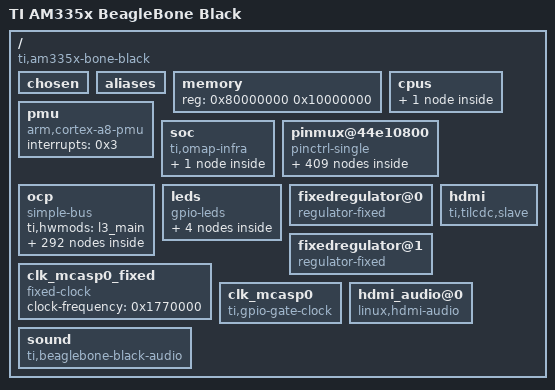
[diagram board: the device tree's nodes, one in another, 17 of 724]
/dts-v1/;

/ {
	#address-cells = <0x1>;
	#size-cells = <0x1>;
	compatible = "ti,am335x-bone-black", "ti,am335x-bone", "ti,am33xx";
	interrupt-parent = <0x1>;
	model = "TI AM335x BeagleBone Black";

	chosen {
	};

	aliases {
		i2c0 = "/ocp/i2c@44e0b000";
		i2c1 = "/ocp/i2c@4802a000";
		i2c2 = "/ocp/i2c@4819c000";
		serial0 = "/ocp/serial@44e09000";
		serial1 = "/ocp/serial@48022000";
		serial2 = "/ocp/serial@48024000";
		serial3 = "/ocp/serial@481a6000";
		serial4 = "/ocp/serial@481a8000";
		serial5 = "/ocp/serial@481aa000";
		d_can0 = "/ocp/d_can@481cc000";
		d_can1 = "/ocp/d_can@481d0000";
		usb0 = "/ocp/usb@47400000/usb@47401000";
		usb1 = "/ocp/usb@47400000/usb@47401800";
		phy0 = "/ocp/usb@47400000/usb-phy@47401300";
		phy1 = "/ocp/usb@47400000/usb-phy@47401b00";
		ethernet0 = "/ocp/ethernet@4a100000/slave@4a100200";
		ethernet1 = "/ocp/ethernet@4a100000/slave@4a100300";
	};

	memory {
		device_type = "memory";
		reg = <0x80000000 0x10000000>;
	};

	cpus {
		#address-cells = <0x1>;
		#size-cells = <0x0>;

		cpu@0 {
			compatible = "arm,cortex-a8";
			device_type = "cpu";
			reg = <0x0>;
			voltage-tolerance = <0x2>;
			clocks = <0x2>;
			clock-names = "cpu";
			clock-latency = <0x493e0>;
			cpu0-supply = <0x3>;
		};
	};

	pmu {
		compatible = "arm,cortex-a8-pmu";
		interrupts = <0x3>;
	};

	soc {
		compatible = "ti,omap-infra";

		mpu {
			compatible = "ti,omap3-mpu";
			ti,hwmods = "mpu";
		};
	};

	pinmux@44e10800 {
		compatible = "pinctrl-single";
		reg = <0x44e10800 0x238>;
		#address-cells = <0x1>;
		#size-cells = <0x0>;
		pinctrl-single,register-width = <0x20>;
		pinctrl-single,function-mask = <0x7f>;
		pinctrl-names = "default";
		pinctrl-0 = <0x4>;

		user_leds_default {
			pinctrl-single,pins = <0x54 0x7 0x58 0x17 0x5c 0x7 0x60 0x17>;
			linux,phandle = <0x1b0>;
			phandle = <0x1b0>;
		};

		user_leds_sleep {
			pinctrl-single,pins = <0x54 0x27 0x58 0x27 0x5c 0x27 0x60 0x27>;
			linux,phandle = <0x1b1>;
			phandle = <0x1b1>;
		};

		user_leds_s1 {
			pinctrl-single,pins = <0x98 0x7 0x9c 0x7>;
		};

		pinmux_gpio1_17_pins {
			pinctrl-single,pins = <0x44 0x27>;
		};

		pinmux_gpio1_18_led_pins {
			pinctrl-single,pins = <0x48 0x7>;
		};

		pinmux_gpio1_28_led_pins {
			pinctrl-single,pins = <0x78 0x2f>;
		};

		pinmux_gpio1_29_pins {
			pinctrl-single,pins = <0x7c 0x3f>;
		};

		pinmux_gpio3_19_led_pins {
			pinctrl-single,pins = <0x1a4 0x7>;
		};

		bbcape_backlight_pins {
			pinctrl-single,pins = <0x48 0xf>;
		};

		pinmux_i2c0_pins {
			pinctrl-single,pins = <0x188 0x30 0x18c 0x30>;
			linux,phandle = <0x26>;
			phandle = <0x26>;
		};

		pinmux_i2c1_pins {
			pinctrl-single,pins = <0x158 0x72 0x15c 0x72>;
		};

		pinmux_i2c2_pins {
			pinctrl-single,pins = <0x178 0x73 0x17c 0x73>;
			linux,phandle = <0x27>;
			phandle = <0x27>;
		};

		pinmux_spi0_pins {
			pinctrl-single,pins = <0x150 0x30 0x154 0x30 0x158 0x10 0x15c 0x10>;
		};

		pinmux_spi1_pins {
			pinctrl-single,pins = <0x190 0x33 0x194 0x33 0x198 0x13 0x19c 0x13>;
		};

		pinmux_spi1a_pins {
			pinctrl-single,pins = <0x164 0x34 0x194 0x33 0x198 0x13 0x178 0x14>;
		};

		pinmux_uart0_pins {
			pinctrl-single,pins = <0x170 0x30 0x174 0x0>;
			linux,phandle = <0x25>;
			phandle = <0x25>;
		};

		pinmux_bbcape_crypto_pins {
			pinctrl-single,pins = <0x44 0x17 0x34 0x2f>;
		};

		bbcape_lcd_pins {
			pinctrl-single,pins = <0xa0 0x8 0xa4 0x8 0xa8 0x8 0xac 0x8 0xb0 0x8 0xb4 0x8 0xb8 0x8 0xbc 0x8 0xc0 0x8 0xc4 0x8 0xc8 0x8 0xcc 0x8 0xd0 0x8 0xd4 0x8 0xd8 0x8 0xdc 0x8 0xe0 0x8 0xe4 0x8 0xe8 0x8 0xec 0x8>;
		};

		bbcape_lcd_24bit_pins {
			pinctrl-single,pins = <0xa0 0x0 0xa4 0x0 0xa8 0x0 0xac 0x0 0xb0 0x0 0xb4 0x0 0xb8 0x0 0xbc 0x0 0xc0 0x0 0xc4 0x0 0xc8 0x0 0xcc 0x0 0xd0 0x0 0xd4 0x0 0xd8 0x0 0xdc 0x0 0x3c 0x11 0x38 0x11 0x34 0x11 0x30 0x11 0x2c 0x11 0x28 0x11 0x24 0x11 0x20 0x11 0xe0 0x0 0xe4 0x0 0xe8 0x0 0xec 0x0>;
		};

		bbcape_lcd7_avdd_en {
			pinctrl-single,pins = <0x150 0x17>;
		};

		bbcape_lcd4_disen_pins {
			pinctrl-single,pins = <0x1a4 0x17>;
		};

		pinmux_clkout2_pin {
			pinctrl-single,pins = <0x1b4 0x3>;
			linux,phandle = <0x4>;
			phandle = <0x4>;
		};

		cpsw_default {
			pinctrl-single,pins = <0x110 0x30 0x114 0x0 0x118 0x30 0x11c 0x0 0x120 0x0 0x124 0x0 0x128 0x0 0x12c 0x30 0x130 0x30 0x134 0x30 0x138 0x30 0x13c 0x30 0x140 0x30>;
			linux,phandle = <0x35>;
			phandle = <0x35>;
		};

		cpsw_sleep {
			pinctrl-single,pins = <0x110 0x27 0x114 0x27 0x118 0x27 0x11c 0x27 0x120 0x27 0x124 0x27 0x128 0x27 0x12c 0x27 0x130 0x27 0x134 0x27 0x138 0x27 0x13c 0x27 0x140 0x27>;
			linux,phandle = <0x36>;
			phandle = <0x36>;
		};

		davinci_mdio_default {
			pinctrl-single,pins = <0x148 0x70 0x14c 0x10>;
			linux,phandle = <0x37>;
			phandle = <0x37>;
		};

		davinci_mdio_sleep {
			pinctrl-single,pins = <0x148 0x27 0x14c 0x27>;
			linux,phandle = <0x38>;
			phandle = <0x38>;
		};

		pinmux_mmc1_pins {
			pinctrl-single,pins = <0xf0 0x30 0xf4 0x30 0xf8 0x30 0xfc 0x30 0x100 0x30 0x104 0x30 0x1a0 0x37 0x160 0x2f>;
			linux,phandle = <0x29>;
			phandle = <0x29>;
		};

		pinmux_mmc1_pins_sleep {
			pinctrl-single,pins = <0xf0 0x27 0xf4 0x27 0xf8 0x27 0xfc 0x27 0x100 0x27 0x104 0x27 0x1a0 0x27>;
			linux,phandle = <0x2a>;
			phandle = <0x2a>;
		};

		pinmux_emmc_pins {
			pinctrl-single,pins = <0x80 0x32 0x84 0x32 0x0 0x31 0x4 0x31 0x8 0x31 0xc 0x31 0x10 0x31 0x14 0x31 0x18 0x31 0x1c 0x31>;
			linux,phandle = <0x2d>;
			phandle = <0x2d>;
		};

		nxp_hdmi_bonelt_pins {
			pinctrl-single,pins = <0x1b0 0x3 0xa0 0x8 0xa4 0x8 0xa8 0x8 0xac 0x8 0xb0 0x8 0xb4 0x8 0xb8 0x8 0xbc 0x8 0xc0 0x8 0xc4 0x8 0xc8 0x8 0xcc 0x8 0xd0 0x8 0xd4 0x8 0xd8 0x8 0xdc 0x8 0xe0 0x0 0xe4 0x0 0xe8 0x0 0xec 0x0>;
		};

		nxp_hdmi_bonelt_off_pins {
			pinctrl-single,pins = <0x1b0 0x3>;
			linux,phandle = <0x1b3>;
			phandle = <0x1b3>;
		};

		pinmux_keymap0_pins {
			pinctrl-single,pins = <0x40 0x2f 0x44 0x2f 0x4c 0x2f 0x198 0x2f 0x154 0x2f>;
		};

		pinmux_keymap1_pins {
			pinctrl-single,pins = <0x40 0x2f 0x44 0x2f 0x4c 0x2f 0x198 0x2f 0x184 0x2f>;
		};

		pinmux_keymap2_pins {
			pinctrl-single,pins = <0x40 0x2f 0x44 0x2f 0x4c 0x2f 0x198 0x2f 0x1a4 0x2f>;
		};

		pinmux_keymap3_pins {
			pinctrl-single,pins = <0x40 0x2f 0x4c 0x2f 0x78 0x2f 0x164 0x2f 0x1a4 0x2f>;
		};

		pinmux_keymap4_pins {
			pinctrl-single,pins = <0x44 0x2f 0x4c 0x2f 0x70 0x2f 0x184 0x2f>;
		};

		mcasp0_pins {
			pinctrl-single,pins = <0x1ac 0x30 0x19c 0x2 0x194 0x10 0x190 0x0 0x6c 0x7>;
		};

		mcasp0_pins_sleep {
			pinctrl-single,pins = <0x1ac 0x27 0x19c 0x27 0x194 0x27 0x190 0x27 0x6c 0x27>;
		};

		mcasp0_clken {
			pinctrl-single,pins = <0x6c 0x7>;
			linux,phandle = <0x3e>;
			phandle = <0x3e>;
		};

		mcasp0_pins_audio_reva {
			pinctrl-single,pins = <0x190 0x20 0x194 0x20 0x19c 0x22 0x1ac 0x22>;
		};

		mcasp0_pins_audio_revb {
			pinctrl-single,pins = <0x1ac 0x0 0x190 0x20 0x194 0x20 0x198 0x20 0x19c 0x22>;
		};

		mcasp0_pins_audio2 {
			pinctrl-single,pins = <0x190 0x20 0x194 0x20 0x198 0x20 0x19c 0x22>;
		};

		pinmux_P8_07_default_pin {
			pinctrl-single,pins = <0x90 0x37>;
			linux,phandle = <0x3f>;
			phandle = <0x3f>;
		};

		pinmux_P8_07_gpio_pin {
			pinctrl-single,pins = <0x90 0x2f>;
			linux,phandle = <0x40>;
			phandle = <0x40>;
		};

		pinmux_P8_07_gpio_pu_pin {
			pinctrl-single,pins = <0x90 0x37>;
			linux,phandle = <0x41>;
			phandle = <0x41>;
		};

		pinmux_P8_07_gpio_pd_pin {
			pinctrl-single,pins = <0x90 0x27>;
			linux,phandle = <0x42>;
			phandle = <0x42>;
		};

		pinmux_P8_07_timer_pin {
			pinctrl-single,pins = <0x90 0x32>;
			linux,phandle = <0x43>;
			phandle = <0x43>;
		};

		pinmux_P8_08_default_pin {
			pinctrl-single,pins = <0x94 0x37>;
			linux,phandle = <0x44>;
			phandle = <0x44>;
		};

		pinmux_P8_08_gpio_pin {
			pinctrl-single,pins = <0x94 0x2f>;
			linux,phandle = <0x45>;
			phandle = <0x45>;
		};

		pinmux_P8_08_gpio_pu_pin {
			pinctrl-single,pins = <0x94 0x37>;
			linux,phandle = <0x46>;
			phandle = <0x46>;
		};

		pinmux_P8_08_gpio_pd_pin {
			pinctrl-single,pins = <0x94 0x27>;
			linux,phandle = <0x47>;
			phandle = <0x47>;
		};

		pinmux_P8_08_timer_pin {
			pinctrl-single,pins = <0x94 0x32>;
			linux,phandle = <0x48>;
			phandle = <0x48>;
		};

		pinmux_P8_09_default_pin {
			pinctrl-single,pins = <0x9c 0x37>;
			linux,phandle = <0x49>;
			phandle = <0x49>;
		};

		pinmux_P8_09_gpio_pin {
			pinctrl-single,pins = <0x9c 0x2f>;
			linux,phandle = <0x4a>;
			phandle = <0x4a>;
		};

		pinmux_P8_09_gpio_pu_pin {
			pinctrl-single,pins = <0x9c 0x37>;
			linux,phandle = <0x4b>;
			phandle = <0x4b>;
		};

		pinmux_P8_09_gpio_pd_pin {
			pinctrl-single,pins = <0x9c 0x27>;
			linux,phandle = <0x4c>;
			phandle = <0x4c>;
		};

		pinmux_P8_09_timer_pin {
			pinctrl-single,pins = <0x9c 0x32>;
			linux,phandle = <0x4d>;
			phandle = <0x4d>;
		};

		pinmux_P8_10_default_pin {
			pinctrl-single,pins = <0x98 0x37>;
			linux,phandle = <0x4e>;
			phandle = <0x4e>;
		};

		pinmux_P8_10_gpio_pin {
			pinctrl-single,pins = <0x98 0x2f>;
			linux,phandle = <0x4f>;
			phandle = <0x4f>;
		};

		pinmux_P8_10_gpio_pu_pin {
			pinctrl-single,pins = <0x98 0x37>;
			linux,phandle = <0x50>;
			phandle = <0x50>;
		};

		pinmux_P8_10_gpio_pd_pin {
			pinctrl-single,pins = <0x98 0x27>;
			linux,phandle = <0x51>;
			phandle = <0x51>;
		};

		pinmux_P8_10_timer_pin {
			pinctrl-single,pins = <0x98 0x32>;
			linux,phandle = <0x52>;
			phandle = <0x52>;
		};

		pinmux_P8_11_default_pin {
			pinctrl-single,pins = <0x34 0x27>;
			linux,phandle = <0x53>;
			phandle = <0x53>;
		};

		pinmux_P8_11_gpio_pin {
			pinctrl-single,pins = <0x34 0x2f>;
			linux,phandle = <0x54>;
			phandle = <0x54>;
		};

		pinmux_P8_11_gpio_pu_pin {
			pinctrl-single,pins = <0x34 0x37>;
			linux,phandle = <0x55>;
			phandle = <0x55>;
		};

		pinmux_P8_11_gpio_pd_pin {
			pinctrl-single,pins = <0x34 0x27>;
			linux,phandle = <0x56>;
			phandle = <0x56>;
		};

		pinmux_P8_11_pruout_pin {
			pinctrl-single,pins = <0x34 0x26>;
			linux,phandle = <0x57>;
			phandle = <0x57>;
		};

		pinmux_P8_11_qep_pin {
			pinctrl-single,pins = <0x34 0x24>;
			linux,phandle = <0x58>;
			phandle = <0x58>;
		};

		pinmux_P8_12_default_pin {
			pinctrl-single,pins = <0x30 0x27>;
			linux,phandle = <0x59>;
			phandle = <0x59>;
		};

		pinmux_P8_12_gpio_pin {
			pinctrl-single,pins = <0x30 0x2f>;
			linux,phandle = <0x5a>;
			phandle = <0x5a>;
		};

		pinmux_P8_12_gpio_pu_pin {
			pinctrl-single,pins = <0x30 0x37>;
			linux,phandle = <0x5b>;
			phandle = <0x5b>;
		};

		pinmux_P8_12_gpio_pd_pin {
			pinctrl-single,pins = <0x30 0x27>;
			linux,phandle = <0x5c>;
			phandle = <0x5c>;
		};

		pinmux_P8_12_pruout_pin {
			pinctrl-single,pins = <0x30 0x26>;
			linux,phandle = <0x5d>;
			phandle = <0x5d>;
		};

		pinmux_P8_12_qep_pin {
			pinctrl-single,pins = <0x30 0x24>;
			linux,phandle = <0x5e>;
			phandle = <0x5e>;
		};

		pinmux_P8_13_default_pin {
			pinctrl-single,pins = <0x24 0x27>;
			linux,phandle = <0x5f>;
			phandle = <0x5f>;
		};

		pinmux_P8_13_gpio_pin {
			pinctrl-single,pins = <0x24 0x2f>;
			linux,phandle = <0x60>;
			phandle = <0x60>;
		};

		pinmux_P8_13_gpio_pu_pin {
			pinctrl-single,pins = <0x24 0x37>;
			linux,phandle = <0x61>;
			phandle = <0x61>;
		};

		pinmux_P8_13_gpio_pd_pin {
			pinctrl-single,pins = <0x24 0x27>;
			linux,phandle = <0x62>;
			phandle = <0x62>;
		};

		pinmux_P8_13_pwm_pin {
			pinctrl-single,pins = <0x24 0x24>;
			linux,phandle = <0x63>;
			phandle = <0x63>;
		};

		pinmux_P8_14_default_pin {
			pinctrl-single,pins = <0x28 0x27>;
			linux,phandle = <0x64>;
			phandle = <0x64>;
		};

		pinmux_P8_14_gpio_pin {
			pinctrl-single,pins = <0x28 0x2f>;
			linux,phandle = <0x65>;
			phandle = <0x65>;
		};

		pinmux_P8_14_gpio_pu_pin {
			pinctrl-single,pins = <0x28 0x37>;
			linux,phandle = <0x66>;
			phandle = <0x66>;
		};

		pinmux_P8_14_gpio_pd_pin {
			pinctrl-single,pins = <0x28 0x27>;
			linux,phandle = <0x67>;
			phandle = <0x67>;
		};

		pinmux_P8_14_pwm_pin {
			pinctrl-single,pins = <0x28 0x24>;
			linux,phandle = <0x68>;
			phandle = <0x68>;
		};

		pinmux_P8_15_default_pin {
			pinctrl-single,pins = <0x3c 0x27>;
			linux,phandle = <0x69>;
			phandle = <0x69>;
		};

		pinmux_P8_15_gpio_pin {
			pinctrl-single,pins = <0x3c 0x2f>;
			linux,phandle = <0x6a>;
			phandle = <0x6a>;
		};

		pinmux_P8_15_gpio_pu_pin {
			pinctrl-single,pins = <0x3c 0x37>;
			linux,phandle = <0x6b>;
			phandle = <0x6b>;
		};

		pinmux_P8_15_gpio_pd_pin {
			pinctrl-single,pins = <0x3c 0x27>;
			linux,phandle = <0x6c>;
			phandle = <0x6c>;
		};

		pinmux_P8_15_pruin_pin {
			pinctrl-single,pins = <0x3c 0x26>;
			linux,phandle = <0x6d>;
			phandle = <0x6d>;
		};

		pinmux_P8_15_qep_pin {
			pinctrl-single,pins = <0x3c 0x24>;
			linux,phandle = <0x6e>;
			phandle = <0x6e>;
		};

		pinmux_P8_16_default_pin {
			pinctrl-single,pins = <0x38 0x27>;
			linux,phandle = <0x6f>;
			phandle = <0x6f>;
		};

		pinmux_P8_16_gpio_pin {
			pinctrl-single,pins = <0x38 0x2f>;
			linux,phandle = <0x70>;
			phandle = <0x70>;
		};

		pinmux_P8_16_gpio_pu_pin {
			pinctrl-single,pins = <0x38 0x37>;
			linux,phandle = <0x71>;
			phandle = <0x71>;
		};

		pinmux_P8_16_gpio_pd_pin {
			pinctrl-single,pins = <0x38 0x27>;
			linux,phandle = <0x72>;
			phandle = <0x72>;
		};

		pinmux_P8_16_pruin_pin {
			pinctrl-single,pins = <0x38 0x26>;
			linux,phandle = <0x73>;
			phandle = <0x73>;
		};

		pinmux_P8_16_qep_pin {
			pinctrl-single,pins = <0x38 0x24>;
			linux,phandle = <0x74>;
			phandle = <0x74>;
		};

		pinmux_P8_17_default_pin {
			pinctrl-single,pins = <0x2c 0x27>;
			linux,phandle = <0x75>;
			phandle = <0x75>;
		};

		pinmux_P8_17_gpio_pin {
			pinctrl-single,pins = <0x2c 0x2f>;
			linux,phandle = <0x76>;
			phandle = <0x76>;
		};

		pinmux_P8_17_gpio_pu_pin {
			pinctrl-single,pins = <0x2c 0x37>;
			linux,phandle = <0x77>;
			phandle = <0x77>;
		};

		pinmux_P8_17_gpio_pd_pin {
			pinctrl-single,pins = <0x2c 0x27>;
			linux,phandle = <0x78>;
			phandle = <0x78>;
		};

		pinmux_P8_17_pwm_pin {
			pinctrl-single,pins = <0x2c 0x24>;
			linux,phandle = <0x79>;
			phandle = <0x79>;
		};

		pinmux_P8_18_default_pin {
			pinctrl-single,pins = <0x8c 0x27>;
			linux,phandle = <0x7a>;
			phandle = <0x7a>;
		};

		pinmux_P8_18_gpio_pin {
			pinctrl-single,pins = <0x8c 0x2f>;
			linux,phandle = <0x7b>;
			phandle = <0x7b>;
		};

		pinmux_P8_18_gpio_pu_pin {
			pinctrl-single,pins = <0x8c 0x37>;
			linux,phandle = <0x7c>;
			phandle = <0x7c>;
		};

		pinmux_P8_18_gpio_pd_pin {
			pinctrl-single,pins = <0x8c 0x27>;
			linux,phandle = <0x7d>;
			phandle = <0x7d>;
		};

		pinmux_P8_19_default_pin {
			pinctrl-single,pins = <0x20 0x27>;
			linux,phandle = <0x7e>;
			phandle = <0x7e>;
		};

		pinmux_P8_19_gpio_pin {
			pinctrl-single,pins = <0x20 0x2f>;
			linux,phandle = <0x7f>;
			phandle = <0x7f>;
		};

		pinmux_P8_19_gpio_pu_pin {
			pinctrl-single,pins = <0x20 0x37>;
			linux,phandle = <0x80>;
			phandle = <0x80>;
		};

		pinmux_P8_19_gpio_pd_pin {
			pinctrl-single,pins = <0x20 0x27>;
			linux,phandle = <0x81>;
			phandle = <0x81>;
		};

		pinmux_P8_19_pwm_pin {
			pinctrl-single,pins = <0x20 0x24>;
			linux,phandle = <0x82>;
			phandle = <0x82>;
		};

		pinmux_P8_26_default_pin {
			pinctrl-single,pins = <0x7c 0x37>;
			linux,phandle = <0x83>;
			phandle = <0x83>;
		};

		pinmux_P8_26_gpio_pin {
			pinctrl-single,pins = <0x7c 0x2f>;
			linux,phandle = <0x84>;
			phandle = <0x84>;
		};

		pinmux_P8_26_gpio_pu_pin {
			pinctrl-single,pins = <0x7c 0x37>;
			linux,phandle = <0x85>;
			phandle = <0x85>;
		};

		pinmux_P8_26_gpio_pd_pin {
			pinctrl-single,pins = <0x7c 0x27>;
			linux,phandle = <0x86>;
			phandle = <0x86>;
		};

		pinmux_P8_27_default_pin {
			pinctrl-single,pins = <0xe0 0x27>;
			linux,phandle = <0x87>;
			phandle = <0x87>;
		};

		pinmux_P8_27_gpio_pin {
			pinctrl-single,pins = <0xe0 0x2f>;
			linux,phandle = <0x88>;
			phandle = <0x88>;
		};

		pinmux_P8_27_gpio_pu_pin {
			pinctrl-single,pins = <0xe0 0x37>;
			linux,phandle = <0x89>;
			phandle = <0x89>;
		};

		pinmux_P8_27_gpio_pd_pin {
			pinctrl-single,pins = <0xe0 0x27>;
			linux,phandle = <0x8a>;
			phandle = <0x8a>;
		};

		pinmux_P8_27_pruout_pin {
			pinctrl-single,pins = <0xe0 0x5>;
			linux,phandle = <0x8b>;
			phandle = <0x8b>;
		};

		pinmux_P8_27_pruin_pin {
			pinctrl-single,pins = <0xe0 0x26>;
			linux,phandle = <0x8c>;
			phandle = <0x8c>;
		};

		pinmux_P8_27_hdmi_pin {
			pinctrl-single,pins = <0xe0 0x0>;
			linux,phandle = <0x8d>;
			phandle = <0x8d>;
		};

		pinmux_P8_28_default_pin {
			pinctrl-single,pins = <0xe8 0x27>;
			linux,phandle = <0x8e>;
			phandle = <0x8e>;
		};

		pinmux_P8_28_gpio_pin {
			pinctrl-single,pins = <0xe8 0x2f>;
			linux,phandle = <0x8f>;
			phandle = <0x8f>;
		};

		pinmux_P8_28_gpio_pu_pin {
			pinctrl-single,pins = <0xe8 0x37>;
			linux,phandle = <0x90>;
			phandle = <0x90>;
		};

		pinmux_P8_28_gpio_pd_pin {
			pinctrl-single,pins = <0xe8 0x27>;
			linux,phandle = <0x91>;
			phandle = <0x91>;
		};

		pinmux_P8_28_pruout_pin {
			pinctrl-single,pins = <0xe8 0x5>;
			linux,phandle = <0x92>;
			phandle = <0x92>;
		};

		pinmux_P8_28_pruin_pin {
			pinctrl-single,pins = <0xe8 0x26>;
			linux,phandle = <0x93>;
			phandle = <0x93>;
		};

		pinmux_P8_28_hdmi_pin {
			pinctrl-single,pins = <0xe8 0x0>;
			linux,phandle = <0x94>;
			phandle = <0x94>;
		};

		pinmux_P8_29_default_pin {
			pinctrl-single,pins = <0xe4 0x27>;
			linux,phandle = <0x95>;
			phandle = <0x95>;
		};

		pinmux_P8_29_gpio_pin {
			pinctrl-single,pins = <0xe4 0x2f>;
			linux,phandle = <0x96>;
			phandle = <0x96>;
		};

		pinmux_P8_29_gpio_pu_pin {
			pinctrl-single,pins = <0xe4 0x37>;
			linux,phandle = <0x97>;
			phandle = <0x97>;
		};

		pinmux_P8_29_gpio_pd_pin {
			pinctrl-single,pins = <0xe4 0x27>;
			linux,phandle = <0x98>;
			phandle = <0x98>;
		};

		pinmux_P8_29_pruout_pin {
			pinctrl-single,pins = <0xe4 0x5>;
			linux,phandle = <0x99>;
			phandle = <0x99>;
		};

		pinmux_P8_29_pruin_pin {
			pinctrl-single,pins = <0xe4 0x26>;
			linux,phandle = <0x9a>;
			phandle = <0x9a>;
		};

		pinmux_P8_29_hdmi_pin {
			pinctrl-single,pins = <0xe4 0x0>;
			linux,phandle = <0x9b>;
			phandle = <0x9b>;
		};

		pinmux_P8_30_default_pin {
			pinctrl-single,pins = <0xec 0x27>;
			linux,phandle = <0x9c>;
			phandle = <0x9c>;
		};

		pinmux_P8_30_gpio_pin {
			pinctrl-single,pins = <0xec 0x2f>;
			linux,phandle = <0x9d>;
			phandle = <0x9d>;
		};

		pinmux_P8_30_gpio_pu_pin {
			pinctrl-single,pins = <0xec 0x37>;
			linux,phandle = <0x9e>;
			phandle = <0x9e>;
		};

		pinmux_P8_30_gpio_pd_pin {
			pinctrl-single,pins = <0xec 0x27>;
			linux,phandle = <0x9f>;
			phandle = <0x9f>;
		};

		pinmux_P8_30_pruout_pin {
			pinctrl-single,pins = <0xec 0x5>;
			linux,phandle = <0xa0>;
			phandle = <0xa0>;
		};

		pinmux_P8_30_pruin_pin {
			pinctrl-single,pins = <0xec 0x26>;
			linux,phandle = <0xa1>;
			phandle = <0xa1>;
		};

		pinmux_P8_30_hdmi_pin {
			pinctrl-single,pins = <0xec 0x0>;
			linux,phandle = <0xa2>;
			phandle = <0xa2>;
		};

		pinmux_P8_31_default_pin {
			pinctrl-single,pins = <0xd8 0x27>;
			linux,phandle = <0xa3>;
			phandle = <0xa3>;
		};

		pinmux_P8_31_gpio_pin {
			pinctrl-single,pins = <0xd8 0x2f>;
			linux,phandle = <0xa4>;
			phandle = <0xa4>;
		};

		pinmux_P8_31_gpio_pu_pin {
			pinctrl-single,pins = <0xd8 0x37>;
			linux,phandle = <0xa5>;
			phandle = <0xa5>;
		};

		pinmux_P8_31_gpio_pd_pin {
			pinctrl-single,pins = <0xd8 0x27>;
			linux,phandle = <0xa6>;
			phandle = <0xa6>;
		};

		pinmux_P8_31_uart_pin {
			pinctrl-single,pins = <0xd8 0x24>;
			linux,phandle = <0xa7>;
			phandle = <0xa7>;
		};

		pinmux_P8_31_hdmi_pin {
			pinctrl-single,pins = <0xd8 0x8>;
			linux,phandle = <0xa8>;
			phandle = <0xa8>;
		};

		pinmux_P8_32_default_pin {
			pinctrl-single,pins = <0xdc 0x27>;
			linux,phandle = <0xa9>;
			phandle = <0xa9>;
		};

		pinmux_P8_32_gpio_pin {
			pinctrl-single,pins = <0xdc 0x2f>;
			linux,phandle = <0xaa>;
			phandle = <0xaa>;
		};

		pinmux_P8_32_gpio_pu_pin {
			pinctrl-single,pins = <0xdc 0x37>;
			linux,phandle = <0xab>;
			phandle = <0xab>;
		};

		pinmux_P8_32_gpio_pd_pin {
			pinctrl-single,pins = <0xdc 0x27>;
			linux,phandle = <0xac>;
			phandle = <0xac>;
		};

		pinmux_P8_32_uart_pin {
			pinctrl-single,pins = <0xdc 0x26>;
		};

		pinmux_P8_32_hdmi_pin {
			pinctrl-single,pins = <0xdc 0x8>;
			linux,phandle = <0xad>;
			phandle = <0xad>;
		};

		pinmux_P8_33_default_pin {
			pinctrl-single,pins = <0xd4 0x27>;
			linux,phandle = <0xae>;
			phandle = <0xae>;
		};

		pinmux_P8_33_gpio_pin {
			pinctrl-single,pins = <0xd4 0x2f>;
			linux,phandle = <0xaf>;
			phandle = <0xaf>;
		};

		pinmux_P8_33_gpio_pu_pin {
			pinctrl-single,pins = <0xd4 0x37>;
			linux,phandle = <0xb0>;
			phandle = <0xb0>;
		};

		pinmux_P8_33_gpio_pd_pin {
			pinctrl-single,pins = <0xd4 0x27>;
			linux,phandle = <0xb1>;
			phandle = <0xb1>;
		};

		pinmux_P8_33_hdmi_pin {
			pinctrl-single,pins = <0xd4 0x8>;
			linux,phandle = <0xb2>;
			phandle = <0xb2>;
		};

		pinmux_P8_34_default_pin {
			pinctrl-single,pins = <0xcc 0x27>;
			linux,phandle = <0xb3>;
			phandle = <0xb3>;
		};

		pinmux_P8_34_gpio_pin {
			pinctrl-single,pins = <0xcc 0x2f>;
			linux,phandle = <0xb4>;
			phandle = <0xb4>;
		};

		pinmux_P8_34_gpio_pu_pin {
			pinctrl-single,pins = <0xcc 0x37>;
			linux,phandle = <0xb5>;
			phandle = <0xb5>;
		};

		pinmux_P8_34_gpio_pd_pin {
			pinctrl-single,pins = <0xcc 0x27>;
			linux,phandle = <0xb6>;
			phandle = <0xb6>;
		};

		pinmux_P8_34_pwm_pin {
			pinctrl-single,pins = <0xcc 0x22>;
			linux,phandle = <0xb7>;
			phandle = <0xb7>;
		};

		pinmux_P8_34_hdmi_pin {
			pinctrl-single,pins = <0xcc 0x8>;
			linux,phandle = <0xb8>;
			phandle = <0xb8>;
		};

		pinmux_P8_35_default_pin {
			pinctrl-single,pins = <0xd0 0x27>;
			linux,phandle = <0xb9>;
			phandle = <0xb9>;
		};

		pinmux_P8_35_gpio_pin {
			pinctrl-single,pins = <0xd0 0x2f>;
			linux,phandle = <0xba>;
			phandle = <0xba>;
		};

		pinmux_P8_35_gpio_pu_pin {
			pinctrl-single,pins = <0xd0 0x37>;
			linux,phandle = <0xbb>;
			phandle = <0xbb>;
		};

		pinmux_P8_35_gpio_pd_pin {
			pinctrl-single,pins = <0xd0 0x27>;
			linux,phandle = <0xbc>;
			phandle = <0xbc>;
		};

		pinmux_P8_35_hdmi_pin {
			pinctrl-single,pins = <0xd0 0x8>;
			linux,phandle = <0xbd>;
			phandle = <0xbd>;
		};

		pinmux_P8_36_default_pin {
			pinctrl-single,pins = <0xc8 0x27>;
			linux,phandle = <0xbe>;
			phandle = <0xbe>;
		};

		pinmux_P8_36_gpio_pin {
			pinctrl-single,pins = <0xc8 0x2f>;
			linux,phandle = <0xbf>;
			phandle = <0xbf>;
		};

		pinmux_P8_36_gpio_pu_pin {
			pinctrl-single,pins = <0xc8 0x37>;
			linux,phandle = <0xc0>;
			phandle = <0xc0>;
		};

		pinmux_P8_36_gpio_pd_pin {
			pinctrl-single,pins = <0xc8 0x27>;
			linux,phandle = <0xc1>;
			phandle = <0xc1>;
		};

		pinmux_P8_36_pwm_pin {
			pinctrl-single,pins = <0xc8 0x22>;
			linux,phandle = <0xc2>;
			phandle = <0xc2>;
		};

		pinmux_P8_36_hdmi_pin {
			pinctrl-single,pins = <0xc8 0x8>;
			linux,phandle = <0xc3>;
			phandle = <0xc3>;
		};

		pinmux_P8_37_default_pin {
			pinctrl-single,pins = <0xc0 0x27>;
			linux,phandle = <0xc4>;
			phandle = <0xc4>;
		};

		pinmux_P8_37_gpio_pin {
			pinctrl-single,pins = <0xc0 0x2f>;
			linux,phandle = <0xc5>;
			phandle = <0xc5>;
		};

		pinmux_P8_37_gpio_pu_pin {
			pinctrl-single,pins = <0xc0 0x37>;
			linux,phandle = <0xc6>;
			phandle = <0xc6>;
		};

		pinmux_P8_37_gpio_pd_pin {
			pinctrl-single,pins = <0xc0 0x27>;
			linux,phandle = <0xc7>;
			phandle = <0xc7>;
		};

		pinmux_P8_37_uart_pin {
			pinctrl-single,pins = <0xc0 0x4>;
			linux,phandle = <0xc8>;
			phandle = <0xc8>;
		};

		pinmux_P8_37_pwm_pin {
			pinctrl-single,pins = <0xc0 0x2>;
			linux,phandle = <0xc9>;
			phandle = <0xc9>;
		};

		pinmux_P8_37_hdmi_pin {
			pinctrl-single,pins = <0xc0 0x8>;
			linux,phandle = <0xca>;
			phandle = <0xca>;
		};

		pinmux_P8_38_default_pin {
			pinctrl-single,pins = <0xc4 0x27>;
			linux,phandle = <0xcb>;
			phandle = <0xcb>;
		};

		pinmux_P8_38_gpio_pin {
			pinctrl-single,pins = <0xc4 0x2f>;
			linux,phandle = <0xcc>;
			phandle = <0xcc>;
		};

		pinmux_P8_38_gpio_pu_pin {
			pinctrl-single,pins = <0xc4 0x37>;
			linux,phandle = <0xcd>;
			phandle = <0xcd>;
		};

		pinmux_P8_38_gpio_pd_pin {
			pinctrl-single,pins = <0xc4 0x27>;
			linux,phandle = <0xce>;
			phandle = <0xce>;
		};

		pinmux_P8_38_uart_pin {
			pinctrl-single,pins = <0xc4 0x24>;
			linux,phandle = <0xcf>;
			phandle = <0xcf>;
		};

		pinmux_P8_38_pwm_pin {
			pinctrl-single,pins = <0xc4 0x22>;
			linux,phandle = <0xd0>;
			phandle = <0xd0>;
		};

		pinmux_P8_38_hdmi_pin {
			pinctrl-single,pins = <0xc4 0x8>;
			linux,phandle = <0xd1>;
			phandle = <0xd1>;
		};

		pinmux_P8_39_default_pin {
			pinctrl-single,pins = <0xb8 0x27>;
			linux,phandle = <0xd2>;
			phandle = <0xd2>;
		};

		pinmux_P8_39_gpio_pin {
			pinctrl-single,pins = <0xb8 0x2f>;
			linux,phandle = <0xd3>;
			phandle = <0xd3>;
		};

		pinmux_P8_39_gpio_pu_pin {
			pinctrl-single,pins = <0xb8 0x37>;
			linux,phandle = <0xd4>;
			phandle = <0xd4>;
		};

		pinmux_P8_39_gpio_pd_pin {
			pinctrl-single,pins = <0xb8 0x27>;
			linux,phandle = <0xd5>;
			phandle = <0xd5>;
		};

		pinmux_P8_39_pruout_pin {
			pinctrl-single,pins = <0xb8 0x5>;
			linux,phandle = <0xd6>;
			phandle = <0xd6>;
		};

		pinmux_P8_39_pruin_pin {
			pinctrl-single,pins = <0xb8 0x26>;
			linux,phandle = <0xd7>;
			phandle = <0xd7>;
		};

		pinmux_P8_39_hdmi_pin {
			pinctrl-single,pins = <0xb8 0x8>;
			linux,phandle = <0xd8>;
			phandle = <0xd8>;
		};

		pinmux_P8_40_default_pin {
			pinctrl-single,pins = <0xbc 0x27>;
			linux,phandle = <0xd9>;
			phandle = <0xd9>;
		};

		pinmux_P8_40_gpio_pin {
			pinctrl-single,pins = <0xbc 0x2f>;
			linux,phandle = <0xda>;
			phandle = <0xda>;
		};

		pinmux_P8_40_gpio_pu_pin {
			pinctrl-single,pins = <0xbc 0x37>;
			linux,phandle = <0xdb>;
			phandle = <0xdb>;
		};

		pinmux_P8_40_gpio_pd_pin {
			pinctrl-single,pins = <0xbc 0x27>;
			linux,phandle = <0xdc>;
			phandle = <0xdc>;
		};

		pinmux_P8_40_pruout_pin {
			pinctrl-single,pins = <0xbc 0x5>;
			linux,phandle = <0xdd>;
			phandle = <0xdd>;
		};

		pinmux_P8_40_pruin_pin {
			pinctrl-single,pins = <0xbc 0x26>;
			linux,phandle = <0xde>;
			phandle = <0xde>;
		};

		pinmux_P8_40_hdmi_pin {
			pinctrl-single,pins = <0xbc 0x8>;
			linux,phandle = <0xdf>;
			phandle = <0xdf>;
		};

		pinmux_P8_41_default_pin {
			pinctrl-single,pins = <0xb0 0x27>;
			linux,phandle = <0xe0>;
			phandle = <0xe0>;
		};

		pinmux_P8_41_gpio_pin {
			pinctrl-single,pins = <0xb0 0x2f>;
			linux,phandle = <0xe1>;
			phandle = <0xe1>;
		};

		pinmux_P8_41_gpio_pu_pin {
			pinctrl-single,pins = <0xb0 0x37>;
			linux,phandle = <0xe2>;
			phandle = <0xe2>;
		};

		pinmux_P8_41_gpio_pd_pin {
			pinctrl-single,pins = <0xb0 0x27>;
			linux,phandle = <0xe3>;
			phandle = <0xe3>;
		};

		pinmux_P8_41_pruout_pin {
			pinctrl-single,pins = <0xb0 0x5>;
			linux,phandle = <0xe4>;
			phandle = <0xe4>;
		};

		pinmux_P8_41_pruin_pin {
			pinctrl-single,pins = <0xb0 0x26>;
			linux,phandle = <0xe5>;
			phandle = <0xe5>;
		};

		pinmux_P8_41_hdmi_pin {
			pinctrl-single,pins = <0xb0 0x8>;
			linux,phandle = <0xe6>;
			phandle = <0xe6>;
		};

		pinmux_P8_42_default_pin {
			pinctrl-single,pins = <0xb4 0x27>;
			linux,phandle = <0xe7>;
			phandle = <0xe7>;
		};

		pinmux_P8_42_gpio_pin {
			pinctrl-single,pins = <0xb4 0x2f>;
			linux,phandle = <0xe8>;
			phandle = <0xe8>;
		};

		pinmux_P8_42_gpio_pu_pin {
			pinctrl-single,pins = <0xb4 0x37>;
			linux,phandle = <0xe9>;
			phandle = <0xe9>;
		};

		pinmux_P8_42_gpio_pd_pin {
			pinctrl-single,pins = <0xb4 0x27>;
			linux,phandle = <0xea>;
			phandle = <0xea>;
		};

		pinmux_P8_42_pruout_pin {
			pinctrl-single,pins = <0xb4 0x5>;
			linux,phandle = <0xeb>;
			phandle = <0xeb>;
		};

		pinmux_P8_42_pruin_pin {
			pinctrl-single,pins = <0xb4 0x26>;
			linux,phandle = <0xec>;
			phandle = <0xec>;
		};

		pinmux_P8_42_hdmi_pin {
			pinctrl-single,pins = <0xb4 0x8>;
			linux,phandle = <0xed>;
			phandle = <0xed>;
		};

		pinmux_P8_43_default_pin {
			pinctrl-single,pins = <0xa8 0x27>;
			linux,phandle = <0xee>;
			phandle = <0xee>;
		};

		pinmux_P8_43_gpio_pin {
			pinctrl-single,pins = <0xa8 0x2f>;
			linux,phandle = <0xef>;
			phandle = <0xef>;
		};

		pinmux_P8_43_gpio_pu_pin {
			pinctrl-single,pins = <0xa8 0x37>;
			linux,phandle = <0xf0>;
			phandle = <0xf0>;
		};

		pinmux_P8_43_gpio_pd_pin {
			pinctrl-single,pins = <0xa8 0x27>;
			linux,phandle = <0xf1>;
			phandle = <0xf1>;
		};

		pinmux_P8_43_pruout_pin {
			pinctrl-single,pins = <0xa8 0x5>;
			linux,phandle = <0xf2>;
			phandle = <0xf2>;
		};

		pinmux_P8_43_pruin_pin {
			pinctrl-single,pins = <0xa8 0x26>;
			linux,phandle = <0xf3>;
			phandle = <0xf3>;
		};

		pinmux_P8_43_pwm_pin {
			pinctrl-single,pins = <0xa8 0x3>;
			linux,phandle = <0xf4>;
			phandle = <0xf4>;
		};

		pinmux_P8_43_hdmi_pin {
			pinctrl-single,pins = <0xa8 0x8>;
			linux,phandle = <0xf5>;
			phandle = <0xf5>;
		};

		pinmux_P8_44_default_pin {
			pinctrl-single,pins = <0xac 0x27>;
			linux,phandle = <0xf6>;
			phandle = <0xf6>;
		};

		pinmux_P8_44_gpio_pin {
			pinctrl-single,pins = <0xac 0x2f>;
			linux,phandle = <0xf7>;
			phandle = <0xf7>;
		};

		pinmux_P8_44_gpio_pu_pin {
			pinctrl-single,pins = <0xac 0x37>;
			linux,phandle = <0xf8>;
			phandle = <0xf8>;
		};

		pinmux_P8_44_gpio_pd_pin {
			pinctrl-single,pins = <0xac 0x27>;
			linux,phandle = <0xf9>;
			phandle = <0xf9>;
		};

		pinmux_P8_44_pruout_pin {
			pinctrl-single,pins = <0xac 0x5>;
			linux,phandle = <0xfa>;
			phandle = <0xfa>;
		};

		pinmux_P8_44_pruin_pin {
			pinctrl-single,pins = <0xac 0x26>;
			linux,phandle = <0xfb>;
			phandle = <0xfb>;
		};

		pinmux_P8_44_pwm_pin {
			pinctrl-single,pins = <0xac 0x23>;
			linux,phandle = <0xfc>;
			phandle = <0xfc>;
		};

		pinmux_P8_44_hdmi_pin {
			pinctrl-single,pins = <0xac 0x8>;
			linux,phandle = <0xfd>;
			phandle = <0xfd>;
		};

		pinmux_P8_45_default_pin {
			pinctrl-single,pins = <0xa0 0x27>;
			linux,phandle = <0xfe>;
			phandle = <0xfe>;
		};

		pinmux_P8_45_gpio_pin {
			pinctrl-single,pins = <0xa0 0x2f>;
			linux,phandle = <0xff>;
			phandle = <0xff>;
		};

		pinmux_P8_45_gpio_pu_pin {
			pinctrl-single,pins = <0xa0 0x37>;
			linux,phandle = <0x100>;
			phandle = <0x100>;
		};

		pinmux_P8_45_gpio_pd_pin {
			pinctrl-single,pins = <0xa0 0x27>;
			linux,phandle = <0x101>;
			phandle = <0x101>;
		};

		pinmux_P8_45_pruout_pin {
			pinctrl-single,pins = <0xa0 0x5>;
			linux,phandle = <0x102>;
			phandle = <0x102>;
		};

		pinmux_P8_45_pruin_pin {
			pinctrl-single,pins = <0xa0 0x26>;
			linux,phandle = <0x103>;
			phandle = <0x103>;
		};

		pinmux_P8_45_pwm_pin {
			pinctrl-single,pins = <0xa0 0x3>;
			linux,phandle = <0x104>;
			phandle = <0x104>;
		};

		pinmux_P8_45_hdmi_pin {
			pinctrl-single,pins = <0xa0 0x8>;
			linux,phandle = <0x105>;
			phandle = <0x105>;
		};

		pinmux_P8_46_default_pin {
			pinctrl-single,pins = <0xa4 0x27>;
			linux,phandle = <0x106>;
			phandle = <0x106>;
		};

		pinmux_P8_46_gpio_pin {
			pinctrl-single,pins = <0xa4 0x2f>;
			linux,phandle = <0x107>;
			phandle = <0x107>;
		};

		pinmux_P8_46_gpio_pu_pin {
			pinctrl-single,pins = <0xa4 0x37>;
			linux,phandle = <0x108>;
			phandle = <0x108>;
		};

		pinmux_P8_46_gpio_pd_pin {
			pinctrl-single,pins = <0xa4 0x27>;
			linux,phandle = <0x109>;
			phandle = <0x109>;
		};

		pinmux_P8_46_pruout_pin {
			pinctrl-single,pins = <0xa4 0x5>;
			linux,phandle = <0x10a>;
			phandle = <0x10a>;
		};

		pinmux_P8_46_pruin_pin {
			pinctrl-single,pins = <0xa4 0x26>;
			linux,phandle = <0x10b>;
			phandle = <0x10b>;
		};

		pinmux_P8_46_pwm_pin {
			pinctrl-single,pins = <0xa4 0x3>;
			linux,phandle = <0x10c>;
			phandle = <0x10c>;
		};

		pinmux_P8_46_hdmi_pin {
			pinctrl-single,pins = <0xa4 0x8>;
			linux,phandle = <0x10d>;
			phandle = <0x10d>;
		};

		pinmux_P9_11_default_pin {
			pinctrl-single,pins = <0x70 0x37>;
			linux,phandle = <0x10e>;
			phandle = <0x10e>;
		};

		pinmux_P9_11_gpio_pin {
			pinctrl-single,pins = <0x70 0x2f>;
			linux,phandle = <0x10f>;
			phandle = <0x10f>;
		};

		pinmux_P9_11_gpio_pu_pin {
			pinctrl-single,pins = <0x70 0x37>;
			linux,phandle = <0x110>;
			phandle = <0x110>;
		};

		pinmux_P9_11_gpio_pd_pin {
			pinctrl-single,pins = <0x70 0x27>;
			linux,phandle = <0x111>;
			phandle = <0x111>;
		};

		pinmux_P9_11_uart_pin {
			pinctrl-single,pins = <0x70 0x36>;
			linux,phandle = <0x112>;
			phandle = <0x112>;
		};

		pinmux_P9_12_default_pin {
			pinctrl-single,pins = <0x78 0x37>;
			linux,phandle = <0x113>;
			phandle = <0x113>;
		};

		pinmux_P9_12_gpio_pin {
			pinctrl-single,pins = <0x78 0x2f>;
			linux,phandle = <0x114>;
			phandle = <0x114>;
		};

		pinmux_P9_12_gpio_pu_pin {
			pinctrl-single,pins = <0x78 0x37>;
			linux,phandle = <0x115>;
			phandle = <0x115>;
		};

		pinmux_P9_12_gpio_pd_pin {
			pinctrl-single,pins = <0x78 0x27>;
			linux,phandle = <0x116>;
			phandle = <0x116>;
		};

		pinmux_P9_13_default_pin {
			pinctrl-single,pins = <0x74 0x37>;
			linux,phandle = <0x117>;
			phandle = <0x117>;
		};

		pinmux_P9_13_gpio_pin {
			pinctrl-single,pins = <0x74 0x2f>;
			linux,phandle = <0x118>;
			phandle = <0x118>;
		};

		pinmux_P9_13_gpio_pu_pin {
			pinctrl-single,pins = <0x74 0x37>;
			linux,phandle = <0x119>;
			phandle = <0x119>;
		};

		pinmux_P9_13_gpio_pd_pin {
			pinctrl-single,pins = <0x74 0x27>;
			linux,phandle = <0x11a>;
			phandle = <0x11a>;
		};

		pinmux_P9_13_uart_pin {
			pinctrl-single,pins = <0x74 0x36>;
			linux,phandle = <0x11b>;
			phandle = <0x11b>;
		};

		pinmux_P9_14_default_pin {
			pinctrl-single,pins = <0x48 0x27>;
			linux,phandle = <0x11c>;
			phandle = <0x11c>;
		};

		pinmux_P9_14_gpio_pin {
			pinctrl-single,pins = <0x48 0x2f>;
			linux,phandle = <0x11d>;
			phandle = <0x11d>;
		};

		pinmux_P9_14_gpio_pu_pin {
			pinctrl-single,pins = <0x48 0x37>;
			linux,phandle = <0x11e>;
			phandle = <0x11e>;
		};

		pinmux_P9_14_gpio_pd_pin {
			pinctrl-single,pins = <0x48 0x27>;
			linux,phandle = <0x11f>;
			phandle = <0x11f>;
		};

		pinmux_P9_14_pwm_pin {
			pinctrl-single,pins = <0x48 0x26>;
			linux,phandle = <0x120>;
			phandle = <0x120>;
		};

		pinmux_P9_15_default_pin {
			pinctrl-single,pins = <0x40 0x27>;
			linux,phandle = <0x121>;
			phandle = <0x121>;
		};

		pinmux_P9_15_gpio_pin {
			pinctrl-single,pins = <0x40 0x2f>;
			linux,phandle = <0x122>;
			phandle = <0x122>;
		};

		pinmux_P9_15_gpio_pu_pin {
			pinctrl-single,pins = <0x40 0x37>;
			linux,phandle = <0x123>;
			phandle = <0x123>;
		};

		pinmux_P9_15_gpio_pd_pin {
			pinctrl-single,pins = <0x40 0x27>;
			linux,phandle = <0x124>;
			phandle = <0x124>;
		};

		pinmux_P9_15_pwm_pin {
			pinctrl-single,pins = <0x40 0x26>;
			linux,phandle = <0x125>;
			phandle = <0x125>;
		};

		pinmux_P9_16_default_pin {
			pinctrl-single,pins = <0x4c 0x27>;
			linux,phandle = <0x126>;
			phandle = <0x126>;
		};

		pinmux_P9_16_gpio_pin {
			pinctrl-single,pins = <0x4c 0x2f>;
			linux,phandle = <0x127>;
			phandle = <0x127>;
		};

		pinmux_P9_16_gpio_pu_pin {
			pinctrl-single,pins = <0x4c 0x37>;
			linux,phandle = <0x128>;
			phandle = <0x128>;
		};

		pinmux_P9_16_gpio_pd_pin {
			pinctrl-single,pins = <0x4c 0x27>;
			linux,phandle = <0x129>;
			phandle = <0x129>;
		};

		pinmux_P9_16_pwm_pin {
			pinctrl-single,pins = <0x4c 0x26>;
			linux,phandle = <0x12a>;
			phandle = <0x12a>;
		};

		pinmux_P9_17_default_pin {
			pinctrl-single,pins = <0x15c 0x37>;
			linux,phandle = <0x12b>;
			phandle = <0x12b>;
		};

		pinmux_P9_17_gpio_pin {
			pinctrl-single,pins = <0x15c 0x2f>;
			linux,phandle = <0x12c>;
			phandle = <0x12c>;
		};

		pinmux_P9_17_gpio_pu_pin {
			pinctrl-single,pins = <0x15c 0x37>;
			linux,phandle = <0x12d>;
			phandle = <0x12d>;
		};

		pinmux_P9_17_gpio_pd_pin {
			pinctrl-single,pins = <0x15c 0x27>;
			linux,phandle = <0x12e>;
			phandle = <0x12e>;
		};

		pinmux_P9_17_spi_pin {
			pinctrl-single,pins = <0x15c 0x30>;
			linux,phandle = <0x12f>;
			phandle = <0x12f>;
		};

		pinmux_P9_17_i2c_pin {
			pinctrl-single,pins = <0x15c 0x32>;
			linux,phandle = <0x130>;
			phandle = <0x130>;
		};

		pinmux_P9_17_pwm_pin {
			pinctrl-single,pins = <0x15c 0x33>;
			linux,phandle = <0x131>;
			phandle = <0x131>;
		};

		pinmux_P9_18_default_pin {
			pinctrl-single,pins = <0x158 0x37>;
			linux,phandle = <0x132>;
			phandle = <0x132>;
		};

		pinmux_P9_18_gpio_pin {
			pinctrl-single,pins = <0x158 0x2f>;
			linux,phandle = <0x133>;
			phandle = <0x133>;
		};

		pinmux_P9_18_gpio_pu_pin {
			pinctrl-single,pins = <0x158 0x37>;
			linux,phandle = <0x134>;
			phandle = <0x134>;
		};

		pinmux_P9_18_gpio_pd_pin {
			pinctrl-single,pins = <0x158 0x27>;
			linux,phandle = <0x135>;
			phandle = <0x135>;
		};

		pinmux_P9_18_spi_pin {
			pinctrl-single,pins = <0x158 0x30>;
			linux,phandle = <0x136>;
			phandle = <0x136>;
		};

		pinmux_P9_18_i2c_pin {
			pinctrl-single,pins = <0x158 0x32>;
			linux,phandle = <0x137>;
			phandle = <0x137>;
		};

		pinmux_P9_18_pwm_pin {
			pinctrl-single,pins = <0x158 0x33>;
			linux,phandle = <0x138>;
			phandle = <0x138>;
		};

		pinmux_P9_21_default_pin {
			pinctrl-single,pins = <0x154 0x37>;
			linux,phandle = <0x139>;
			phandle = <0x139>;
		};

		pinmux_P9_21_gpio_pin {
			pinctrl-single,pins = <0x154 0x2f>;
			linux,phandle = <0x13a>;
			phandle = <0x13a>;
		};

		pinmux_P9_21_gpio_pu_pin {
			pinctrl-single,pins = <0x154 0x37>;
			linux,phandle = <0x13b>;
			phandle = <0x13b>;
		};

		pinmux_P9_21_gpio_pd_pin {
			pinctrl-single,pins = <0x154 0x27>;
			linux,phandle = <0x13c>;
			phandle = <0x13c>;
		};

		pinmux_P9_21_spi_pin {
			pinctrl-single,pins = <0x154 0x30>;
			linux,phandle = <0x13d>;
			phandle = <0x13d>;
		};

		pinmux_P9_21_uart_pin {
			pinctrl-single,pins = <0x154 0x31>;
			linux,phandle = <0x13e>;
			phandle = <0x13e>;
		};

		pinmux_P9_21_i2c_pin {
			pinctrl-single,pins = <0x154 0x32>;
			linux,phandle = <0x13f>;
			phandle = <0x13f>;
		};

		pinmux_P9_21_pwm_pin {
			pinctrl-single,pins = <0x154 0x33>;
			linux,phandle = <0x140>;
			phandle = <0x140>;
		};

		pinmux_P9_22_default_pin {
			pinctrl-single,pins = <0x150 0x37>;
			linux,phandle = <0x141>;
			phandle = <0x141>;
		};

		pinmux_P9_22_gpio_pin {
			pinctrl-single,pins = <0x150 0x2f>;
			linux,phandle = <0x142>;
			phandle = <0x142>;
		};

		pinmux_P9_22_gpio_pu_pin {
			pinctrl-single,pins = <0x150 0x37>;
			linux,phandle = <0x143>;
			phandle = <0x143>;
		};

		pinmux_P9_22_gpio_pd_pin {
			pinctrl-single,pins = <0x150 0x27>;
			linux,phandle = <0x144>;
			phandle = <0x144>;
		};

		pinmux_P9_22_spi_pin {
			pinctrl-single,pins = <0x150 0x30>;
			linux,phandle = <0x145>;
			phandle = <0x145>;
		};

		pinmux_P9_22_uart_pin {
			pinctrl-single,pins = <0x150 0x31>;
			linux,phandle = <0x146>;
			phandle = <0x146>;
		};

		pinmux_P9_22_i2c_pin {
			pinctrl-single,pins = <0x150 0x32>;
			linux,phandle = <0x147>;
			phandle = <0x147>;
		};

		pinmux_P9_22_pwm_pin {
			pinctrl-single,pins = <0x150 0x33>;
			linux,phandle = <0x148>;
			phandle = <0x148>;
		};

		pinmux_P9_23_default_pin {
			pinctrl-single,pins = <0x44 0x27>;
			linux,phandle = <0x149>;
			phandle = <0x149>;
		};

		pinmux_P9_23_gpio_pin {
			pinctrl-single,pins = <0x44 0x2f>;
			linux,phandle = <0x14a>;
			phandle = <0x14a>;
		};

		pinmux_P9_23_gpio_pu_pin {
			pinctrl-single,pins = <0x44 0x37>;
			linux,phandle = <0x14b>;
			phandle = <0x14b>;
		};

		pinmux_P9_23_gpio_pd_pin {
			pinctrl-single,pins = <0x44 0x27>;
			linux,phandle = <0x14c>;
			phandle = <0x14c>;
		};

		pinmux_P9_23_pwm_pin {
			pinctrl-single,pins = <0x44 0x26>;
			linux,phandle = <0x14d>;
			phandle = <0x14d>;
		};

		pinmux_P9_24_default_pin {
			pinctrl-single,pins = <0x184 0x37>;
			linux,phandle = <0x14e>;
			phandle = <0x14e>;
		};

		pinmux_P9_24_gpio_pin {
			pinctrl-single,pins = <0x184 0x2f>;
			linux,phandle = <0x14f>;
			phandle = <0x14f>;
		};

		pinmux_P9_24_gpio_pu_pin {
			pinctrl-single,pins = <0x184 0x37>;
			linux,phandle = <0x150>;
			phandle = <0x150>;
		};

		pinmux_P9_24_gpio_pd_pin {
			pinctrl-single,pins = <0x184 0x27>;
			linux,phandle = <0x151>;
			phandle = <0x151>;
		};

		pinmux_P9_24_uart_pin {
			pinctrl-single,pins = <0x184 0x30>;
			linux,phandle = <0x152>;
			phandle = <0x152>;
		};

		pinmux_P9_24_can_pin {
			pinctrl-single,pins = <0x184 0x32>;
			linux,phandle = <0x153>;
			phandle = <0x153>;
		};

		pinmux_P9_24_i2c_pin {
			pinctrl-single,pins = <0x184 0x33>;
			linux,phandle = <0x154>;
			phandle = <0x154>;
		};

		pinmux_P9_24_pruin_pin {
			pinctrl-single,pins = <0x184 0x36>;
			linux,phandle = <0x155>;
			phandle = <0x155>;
		};

		pinmux_P9_25_default_pin {
			pinctrl-single,pins = <0x1ac 0x27>;
			linux,phandle = <0x156>;
			phandle = <0x156>;
		};

		pinmux_P9_25_gpio_pin {
			pinctrl-single,pins = <0x1ac 0x2f>;
			linux,phandle = <0x157>;
			phandle = <0x157>;
		};

		pinmux_P9_25_gpio_pu_pin {
			pinctrl-single,pins = <0x1ac 0x37>;
			linux,phandle = <0x158>;
			phandle = <0x158>;
		};

		pinmux_P9_25_gpio_pd_pin {
			pinctrl-single,pins = <0x1ac 0x27>;
			linux,phandle = <0x159>;
			phandle = <0x159>;
		};

		pinmux_P9_25_qep_pin {
			pinctrl-single,pins = <0x1ac 0x21>;
			linux,phandle = <0x15a>;
			phandle = <0x15a>;
		};

		pinmux_P9_25_pruout_pin {
			pinctrl-single,pins = <0x1ac 0x25>;
			linux,phandle = <0x15b>;
			phandle = <0x15b>;
		};

		pinmux_P9_25_pruin_pin {
			pinctrl-single,pins = <0x1ac 0x26>;
			linux,phandle = <0x15c>;
			phandle = <0x15c>;
		};

		pinmux_P9_25_audio_pin {
			pinctrl-single,pins = <0x1ac 0x30>;
			linux,phandle = <0x15d>;
			phandle = <0x15d>;
		};

		pinmux_P9_26_default_pin {
			pinctrl-single,pins = <0x180 0x37>;
			linux,phandle = <0x15e>;
			phandle = <0x15e>;
		};

		pinmux_P9_26_gpio_pin {
			pinctrl-single,pins = <0x180 0x2f>;
			linux,phandle = <0x15f>;
			phandle = <0x15f>;
		};

		pinmux_P9_26_gpio_pu_pin {
			pinctrl-single,pins = <0x180 0x37>;
			linux,phandle = <0x160>;
			phandle = <0x160>;
		};

		pinmux_P9_26_gpio_pd_pin {
			pinctrl-single,pins = <0x180 0x27>;
			linux,phandle = <0x161>;
			phandle = <0x161>;
		};

		pinmux_P9_26_uart_pin {
			pinctrl-single,pins = <0x180 0x30>;
			linux,phandle = <0x162>;
			phandle = <0x162>;
		};

		pinmux_P9_26_can_pin {
			pinctrl-single,pins = <0x180 0x12>;
			linux,phandle = <0x163>;
			phandle = <0x163>;
		};

		pinmux_P9_26_i2c_pin {
			pinctrl-single,pins = <0x180 0x33>;
			linux,phandle = <0x164>;
			phandle = <0x164>;
		};

		pinmux_P9_26_pruin_pin {
			pinctrl-single,pins = <0x180 0x36>;
			linux,phandle = <0x165>;
			phandle = <0x165>;
		};

		pinmux_P9_27_default_pin {
			pinctrl-single,pins = <0x1a4 0x27>;
			linux,phandle = <0x166>;
			phandle = <0x166>;
		};

		pinmux_P9_27_gpio_pin {
			pinctrl-single,pins = <0x1a4 0x2f>;
			linux,phandle = <0x167>;
			phandle = <0x167>;
		};

		pinmux_P9_27_gpio_pu_pin {
			pinctrl-single,pins = <0x1a4 0x37>;
			linux,phandle = <0x168>;
			phandle = <0x168>;
		};

		pinmux_P9_27_gpio_pd_pin {
			pinctrl-single,pins = <0x1a4 0x27>;
			linux,phandle = <0x169>;
			phandle = <0x169>;
		};

		pinmux_P9_27_qep_pin {
			pinctrl-single,pins = <0x1a4 0x21>;
			linux,phandle = <0x16a>;
			phandle = <0x16a>;
		};

		pinmux_P9_27_pruout_pin {
			pinctrl-single,pins = <0x1a4 0x25>;
			linux,phandle = <0x16b>;
			phandle = <0x16b>;
		};

		pinmux_P9_27_pruin_pin {
			pinctrl-single,pins = <0x1a4 0x26>;
			linux,phandle = <0x16c>;
			phandle = <0x16c>;
		};

		pinmux_P9_28_default_pin {
			pinctrl-single,pins = <0x19c 0x27>;
			linux,phandle = <0x16d>;
			phandle = <0x16d>;
		};

		pinmux_P9_28_gpio_pin {
			pinctrl-single,pins = <0x19c 0x2f>;
			linux,phandle = <0x16e>;
			phandle = <0x16e>;
		};

		pinmux_P9_28_gpio_pu_pin {
			pinctrl-single,pins = <0x19c 0x37>;
			linux,phandle = <0x16f>;
			phandle = <0x16f>;
		};

		pinmux_P9_28_gpio_pd_pin {
			pinctrl-single,pins = <0x19c 0x27>;
			linux,phandle = <0x170>;
			phandle = <0x170>;
		};

		pinmux_P9_28_pwm_pin {
			pinctrl-single,pins = <0x19c 0x21>;
			linux,phandle = <0x171>;
			phandle = <0x171>;
		};

		pinmux_P9_28_spi_pin {
			pinctrl-single,pins = <0x19c 0x23>;
			linux,phandle = <0x172>;
			phandle = <0x172>;
		};

		pinmux_P9_28_pwm2_pin {
			pinctrl-single,pins = <0x19c 0x24>;
			linux,phandle = <0x173>;
			phandle = <0x173>;
		};

		pinmux_P9_28_pruout_pin {
			pinctrl-single,pins = <0x19c 0x25>;
			linux,phandle = <0x174>;
			phandle = <0x174>;
		};

		pinmux_P9_28_pruin_pin {
			pinctrl-single,pins = <0x19c 0x26>;
			linux,phandle = <0x175>;
			phandle = <0x175>;
		};

		pinmux_P9_28_audio_pin {
			pinctrl-single,pins = <0x19c 0x2>;
			linux,phandle = <0x176>;
			phandle = <0x176>;
		};

		pinmux_P9_29_default_pin {
			pinctrl-single,pins = <0x194 0x27>;
			linux,phandle = <0x177>;
			phandle = <0x177>;
		};

		pinmux_P9_29_gpio_pin {
			pinctrl-single,pins = <0x194 0x2f>;
			linux,phandle = <0x178>;
			phandle = <0x178>;
		};

		pinmux_P9_29_gpio_pu_pin {
			pinctrl-single,pins = <0x194 0x37>;
			linux,phandle = <0x179>;
			phandle = <0x179>;
		};

		pinmux_P9_29_gpio_pd_pin {
			pinctrl-single,pins = <0x194 0x27>;
			linux,phandle = <0x17a>;
			phandle = <0x17a>;
		};

		pinmux_P9_29_pwm_pin {
			pinctrl-single,pins = <0x194 0x21>;
			linux,phandle = <0x17b>;
			phandle = <0x17b>;
		};

		pinmux_P9_29_spi_pin {
			pinctrl-single,pins = <0x194 0x23>;
			linux,phandle = <0x17c>;
			phandle = <0x17c>;
		};

		pinmux_P9_29_pruout_pin {
			pinctrl-single,pins = <0x194 0x25>;
			linux,phandle = <0x17d>;
			phandle = <0x17d>;
		};

		pinmux_P9_29_pruin_pin {
			pinctrl-single,pins = <0x194 0x26>;
			linux,phandle = <0x17e>;
			phandle = <0x17e>;
		};

		pinmux_P9_29_audio_pin {
			pinctrl-single,pins = <0x194 0x10>;
			linux,phandle = <0x17f>;
			phandle = <0x17f>;
		};

		pinmux_P9_30_default_pin {
			pinctrl-single,pins = <0x198 0x27>;
			linux,phandle = <0x180>;
			phandle = <0x180>;
		};

		pinmux_P9_30_gpio_pin {
			pinctrl-single,pins = <0x198 0x2f>;
			linux,phandle = <0x181>;
			phandle = <0x181>;
		};

		pinmux_P9_30_gpio_pu_pin {
			pinctrl-single,pins = <0x198 0x37>;
			linux,phandle = <0x182>;
			phandle = <0x182>;
		};

		pinmux_P9_30_gpio_pd_pin {
			pinctrl-single,pins = <0x198 0x27>;
			linux,phandle = <0x183>;
			phandle = <0x183>;
		};

		pinmux_P9_30_pwm_pin {
			pinctrl-single,pins = <0x198 0x21>;
			linux,phandle = <0x184>;
			phandle = <0x184>;
		};

		pinmux_P9_30_spi_pin {
			pinctrl-single,pins = <0x198 0x23>;
			linux,phandle = <0x185>;
			phandle = <0x185>;
		};

		pinmux_P9_30_pruout_pin {
			pinctrl-single,pins = <0x198 0x25>;
			linux,phandle = <0x186>;
			phandle = <0x186>;
		};

		pinmux_P9_30_pruin_pin {
			pinctrl-single,pins = <0x198 0x26>;
			linux,phandle = <0x187>;
			phandle = <0x187>;
		};

		pinmux_P9_31_default_pin {
			pinctrl-single,pins = <0x190 0x27>;
			linux,phandle = <0x188>;
			phandle = <0x188>;
		};

		pinmux_P9_31_gpio_pin {
			pinctrl-single,pins = <0x190 0x2f>;
			linux,phandle = <0x189>;
			phandle = <0x189>;
		};

		pinmux_P9_31_gpio_pu_pin {
			pinctrl-single,pins = <0x190 0x37>;
			linux,phandle = <0x18a>;
			phandle = <0x18a>;
		};

		pinmux_P9_31_gpio_pd_pin {
			pinctrl-single,pins = <0x190 0x27>;
			linux,phandle = <0x18b>;
			phandle = <0x18b>;
		};

		pinmux_P9_31_pwm_pin {
			pinctrl-single,pins = <0x190 0x21>;
			linux,phandle = <0x18c>;
			phandle = <0x18c>;
		};

		pinmux_P9_31_spi_pin {
			pinctrl-single,pins = <0x190 0x23>;
			linux,phandle = <0x18d>;
			phandle = <0x18d>;
		};

		pinmux_P9_31_pruout_pin {
			pinctrl-single,pins = <0x190 0x25>;
			linux,phandle = <0x18e>;
			phandle = <0x18e>;
		};

		pinmux_P9_31_pruin_pin {
			pinctrl-single,pins = <0x190 0x26>;
			linux,phandle = <0x18f>;
			phandle = <0x18f>;
		};

		pinmux_P9_31_audio_pin {
			pinctrl-single,pins = <0x190 0x0>;
			linux,phandle = <0x190>;
			phandle = <0x190>;
		};

		pinmux_P9_41_default_pin {
			pinctrl-single,pins = <0x1b4 0x27>;
			linux,phandle = <0x191>;
			phandle = <0x191>;
		};

		pinmux_P9_41_gpio_pin {
			pinctrl-single,pins = <0x1b4 0x2f>;
			linux,phandle = <0x192>;
			phandle = <0x192>;
		};

		pinmux_P9_41_gpio_pu_pin {
			pinctrl-single,pins = <0x1b4 0x37>;
			linux,phandle = <0x193>;
			phandle = <0x193>;
		};

		pinmux_P9_41_gpio_pd_pin {
			pinctrl-single,pins = <0x1b4 0x27>;
			linux,phandle = <0x194>;
			phandle = <0x194>;
		};

		pinmux_P9_41_timer_pin {
			pinctrl-single,pins = <0x1b4 0x24>;
			linux,phandle = <0x195>;
			phandle = <0x195>;
		};

		pinmux_P9_41_pruin_pin {
			pinctrl-single,pins = <0x1b4 0x25>;
			linux,phandle = <0x196>;
			phandle = <0x196>;
		};

		pinmux_P9_91_default_pin {
			pinctrl-single,pins = <0x1a8 0x27>;
			linux,phandle = <0x197>;
			phandle = <0x197>;
		};

		pinmux_P9_91_gpio_pin {
			pinctrl-single,pins = <0x1a8 0x2f>;
			linux,phandle = <0x198>;
			phandle = <0x198>;
		};

		pinmux_P9_91_gpio_pu_pin {
			pinctrl-single,pins = <0x1a8 0x37>;
			linux,phandle = <0x199>;
			phandle = <0x199>;
		};

		pinmux_P9_91_gpio_pd_pin {
			pinctrl-single,pins = <0x1a8 0x27>;
			linux,phandle = <0x19a>;
			phandle = <0x19a>;
		};

		pinmux_P9_91_qep_pin {
			pinctrl-single,pins = <0x1a8 0x21>;
			linux,phandle = <0x19b>;
			phandle = <0x19b>;
		};

		pinmux_P9_91_pruout_pin {
			pinctrl-single,pins = <0x1a8 0x25>;
			linux,phandle = <0x19c>;
			phandle = <0x19c>;
		};

		pinmux_P9_91_pruin_pin {
			pinctrl-single,pins = <0x1a8 0x26>;
			linux,phandle = <0x19d>;
			phandle = <0x19d>;
		};

		pinmux_P9_42_default_pin {
			pinctrl-single,pins = <0x164 0x27>;
			linux,phandle = <0x19e>;
			phandle = <0x19e>;
		};

		pinmux_P9_42_gpio_pin {
			pinctrl-single,pins = <0x164 0x2f>;
			linux,phandle = <0x19f>;
			phandle = <0x19f>;
		};

		pinmux_P9_42_gpio_pu_pin {
			pinctrl-single,pins = <0x164 0x37>;
			linux,phandle = <0x1a0>;
			phandle = <0x1a0>;
		};

		pinmux_P9_42_gpio_pd_pin {
			pinctrl-single,pins = <0x164 0x27>;
			linux,phandle = <0x1a1>;
			phandle = <0x1a1>;
		};

		pinmux_P9_42_pwm_pin {
			pinctrl-single,pins = <0x164 0x20>;
			linux,phandle = <0x1a2>;
			phandle = <0x1a2>;
		};

		pinmux_P9_42_uart_pin {
			pinctrl-single,pins = <0x164 0x21>;
			linux,phandle = <0x1a3>;
			phandle = <0x1a3>;
		};

		pinmux_P9_42_spics_pin {
			pinctrl-single,pins = <0x164 0x22>;
			linux,phandle = <0x1a4>;
			phandle = <0x1a4>;
		};

		pinmux_P9_42_spiclk_pin {
			pinctrl-single,pins = <0x164 0x24>;
			linux,phandle = <0x1a5>;
			phandle = <0x1a5>;
		};

		pinmux_P9_92_default_pin {
			pinctrl-single,pins = <0x1a0 0x27>;
			linux,phandle = <0x1a6>;
			phandle = <0x1a6>;
		};

		pinmux_P9_92_gpio_pin {
			pinctrl-single,pins = <0x1a0 0x2f>;
			linux,phandle = <0x1a7>;
			phandle = <0x1a7>;
		};

		pinmux_P9_92_gpio_pu_pin {
			pinctrl-single,pins = <0x1a0 0x37>;
			linux,phandle = <0x1a8>;
			phandle = <0x1a8>;
		};

		pinmux_P9_92_gpio_pd_pin {
			pinctrl-single,pins = <0x1a0 0x27>;
			linux,phandle = <0x1a9>;
			phandle = <0x1a9>;
		};

		pinmux_P9_92_qep_pin {
			pinctrl-single,pins = <0x1a0 0x21>;
			linux,phandle = <0x1aa>;
			phandle = <0x1aa>;
		};

		pinmux_P9_92_pruout_pin {
			pinctrl-single,pins = <0x1a0 0x25>;
			linux,phandle = <0x1ab>;
			phandle = <0x1ab>;
		};

		pinmux_P9_92_pruin_pin {
			pinctrl-single,pins = <0x1a0 0x26>;
			linux,phandle = <0x1ac>;
			phandle = <0x1ac>;
		};
	};

	ocp {
		compatible = "simple-bus";
		#address-cells = <0x1>;
		#size-cells = <0x1>;
		ranges;
		ti,hwmods = "l3_main";

		prcm@44e00000 {
			compatible = "ti,am3-prcm";
			reg = <0x44e00000 0x4000>;

			clocks {
				#address-cells = <0x1>;
				#size-cells = <0x0>;

				clk_32768_ck {
					#clock-cells = <0x0>;
					compatible = "fixed-clock";
					clock-frequency = <0x8000>;
					linux,phandle = <0x15>;
					phandle = <0x15>;
				};

				clk_rc32k_ck {
					#clock-cells = <0x0>;
					compatible = "fixed-clock";
					clock-frequency = <0x7d00>;
					linux,phandle = <0x14>;
					phandle = <0x14>;
				};

				virt_19200000_ck {
					#clock-cells = <0x0>;
					compatible = "fixed-clock";
					clock-frequency = <0x124f800>;
					linux,phandle = <0x21>;
					phandle = <0x21>;
				};

				virt_24000000_ck {
					#clock-cells = <0x0>;
					compatible = "fixed-clock";
					clock-frequency = <0x16e3600>;
					linux,phandle = <0x22>;
					phandle = <0x22>;
				};

				virt_25000000_ck {
					#clock-cells = <0x0>;
					compatible = "fixed-clock";
					clock-frequency = <0x17d7840>;
					linux,phandle = <0x23>;
					phandle = <0x23>;
				};

				virt_26000000_ck {
					#clock-cells = <0x0>;
					compatible = "fixed-clock";
					clock-frequency = <0x18cba80>;
					linux,phandle = <0x24>;
					phandle = <0x24>;
				};

				tclkin_ck {
					#clock-cells = <0x0>;
					compatible = "fixed-clock";
					clock-frequency = <0xb71b00>;
					linux,phandle = <0x13>;
					phandle = <0x13>;
				};

				dpll_core_ck {
					#clock-cells = <0x0>;
					compatible = "ti,am3-dpll-core-clock";
					clocks = <0x5 0x5>;
					reg = <0x490 0x45c 0x468>;
					linux,phandle = <0x6>;
					phandle = <0x6>;
				};

				dpll_core_x2_ck {
					#clock-cells = <0x0>;
					compatible = "ti,am3-dpll-x2-clock";
					clocks = <0x6>;
					linux,phandle = <0x7>;
					phandle = <0x7>;
				};

				dpll_core_m4_ck {
					#clock-cells = <0x0>;
					compatible = "ti,divider-clock";
					clocks = <0x7>;
					ti,max-div = <0x1f>;
					reg = <0x480>;
					ti,index-starts-at-one;
					linux,phandle = <0xf>;
					phandle = <0xf>;
				};

				dpll_core_m5_ck {
					#clock-cells = <0x0>;
					compatible = "ti,divider-clock";
					clocks = <0x7>;
					ti,max-div = <0x1f>;
					reg = <0x484>;
					ti,index-starts-at-one;
					linux,phandle = <0x17>;
					phandle = <0x17>;
				};

				dpll_core_m6_ck {
					#clock-cells = <0x0>;
					compatible = "ti,divider-clock";
					clocks = <0x7>;
					ti,max-div = <0x1f>;
					reg = <0x4d8>;
					ti,index-starts-at-one;
				};

				dpll_mpu_ck {
					#clock-cells = <0x0>;
					compatible = "ti,am3-dpll-clock";
					clocks = <0x5 0x5>;
					reg = <0x488 0x420 0x42c>;
					linux,phandle = <0x2>;
					phandle = <0x2>;
				};

				dpll_mpu_m2_ck {
					#clock-cells = <0x0>;
					compatible = "ti,divider-clock";
					clocks = <0x2>;
					ti,max-div = <0x1f>;
					reg = <0x4a8>;
					ti,index-starts-at-one;
				};

				dpll_ddr_ck {
					#clock-cells = <0x0>;
					compatible = "ti,am3-dpll-no-gate-clock";
					clocks = <0x5 0x5>;
					reg = <0x494 0x434 0x440>;
					linux,phandle = <0x8>;
					phandle = <0x8>;
				};

				dpll_ddr_m2_ck {
					#clock-cells = <0x0>;
					compatible = "ti,divider-clock";
					clocks = <0x8>;
					ti,max-div = <0x1f>;
					reg = <0x4a0>;
					ti,index-starts-at-one;
					linux,phandle = <0x9>;
					phandle = <0x9>;
				};

				dpll_ddr_m2_div2_ck {
					#clock-cells = <0x0>;
					compatible = "fixed-factor-clock";
					clocks = <0x9>;
					clock-mult = <0x1>;
					clock-div = <0x2>;
				};

				dpll_disp_ck {
					#clock-cells = <0x0>;
					compatible = "ti,am3-dpll-no-gate-clock";
					clocks = <0x5 0x5>;
					reg = <0x498 0x448 0x454>;
					linux,phandle = <0xa>;
					phandle = <0xa>;
				};

				dpll_disp_m2_ck {
					#clock-cells = <0x0>;
					compatible = "ti,divider-clock";
					clocks = <0xa>;
					ti,max-div = <0x1f>;
					reg = <0x4a4>;
					ti,index-starts-at-one;
					ti,set-rate-parent;
					linux,phandle = <0x11>;
					phandle = <0x11>;
				};

				dpll_per_ck {
					#clock-cells = <0x0>;
					compatible = "ti,am3-dpll-no-gate-j-type-clock";
					clocks = <0x5 0x5>;
					reg = <0x48c 0x470 0x49c>;
					linux,phandle = <0xb>;
					phandle = <0xb>;
				};

				dpll_per_m2_ck {
					#clock-cells = <0x0>;
					compatible = "ti,divider-clock";
					clocks = <0xb>;
					ti,max-div = <0x1f>;
					reg = <0x4ac>;
					ti,index-starts-at-one;
					linux,phandle = <0xc>;
					phandle = <0xc>;
				};

				dpll_per_m2_div4_wkupdm_ck {
					#clock-cells = <0x0>;
					compatible = "fixed-factor-clock";
					clocks = <0xc>;
					clock-mult = <0x1>;
					clock-div = <0x4>;
				};

				dpll_per_m2_div4_ck {
					#clock-cells = <0x0>;
					compatible = "fixed-factor-clock";
					clocks = <0xc>;
					clock-mult = <0x1>;
					clock-div = <0x4>;
				};

				cefuse_fck {
					#clock-cells = <0x0>;
					compatible = "ti,gate-clock";
					clocks = <0x5>;
					ti,bit-shift = <0x1>;
					reg = <0xa20>;
				};

				clk_24mhz {
					#clock-cells = <0x0>;
					compatible = "fixed-factor-clock";
					clocks = <0xc>;
					clock-mult = <0x1>;
					clock-div = <0x8>;
					linux,phandle = <0xd>;
					phandle = <0xd>;
				};

				clkdiv32k_ck {
					#clock-cells = <0x0>;
					compatible = "fixed-factor-clock";
					clocks = <0xd>;
					clock-mult = <0x1>;
					clock-div = <0x2dc>;
					linux,phandle = <0xe>;
					phandle = <0xe>;
				};

				clkdiv32k_ick {
					#clock-cells = <0x0>;
					compatible = "ti,gate-clock";
					clocks = <0xe>;
					ti,bit-shift = <0x1>;
					reg = <0x14c>;
					linux,phandle = <0x12>;
					phandle = <0x12>;
				};

				l3_gclk {
					#clock-cells = <0x0>;
					compatible = "fixed-factor-clock";
					clocks = <0xf>;
					clock-mult = <0x1>;
					clock-div = <0x1>;
					linux,phandle = <0x10>;
					phandle = <0x10>;
				};

				pruss_ocp_gclk {
					#clock-cells = <0x0>;
					compatible = "ti,mux-clock";
					clocks = <0x10 0x11>;
					reg = <0x530>;
				};

				mmu_fck {
					#clock-cells = <0x0>;
					compatible = "ti,gate-clock";
					clocks = <0xf>;
					ti,bit-shift = <0x1>;
					reg = <0x914>;
				};

				timer1_fck {
					#clock-cells = <0x0>;
					compatible = "ti,mux-clock";
					clocks = <0x5 0x12 0x13 0x14 0x15>;
					reg = <0x528>;
				};

				timer2_fck {
					#clock-cells = <0x0>;
					compatible = "ti,mux-clock";
					clocks = <0x13 0x5 0x12>;
					reg = <0x508>;
				};

				timer3_fck {
					#clock-cells = <0x0>;
					compatible = "ti,mux-clock";
					clocks = <0x13 0x5 0x12>;
					reg = <0x50c>;
				};

				timer4_fck {
					#clock-cells = <0x0>;
					compatible = "ti,mux-clock";
					clocks = <0x13 0x5 0x12>;
					reg = <0x510>;
				};

				timer5_fck {
					#clock-cells = <0x0>;
					compatible = "ti,mux-clock";
					clocks = <0x13 0x5 0x12>;
					reg = <0x518>;
				};

				timer6_fck {
					#clock-cells = <0x0>;
					compatible = "ti,mux-clock";
					clocks = <0x13 0x5 0x12>;
					reg = <0x51c>;
				};

				timer7_fck {
					#clock-cells = <0x0>;
					compatible = "ti,mux-clock";
					clocks = <0x13 0x5 0x12>;
					reg = <0x504>;
				};

				usbotg_fck {
					#clock-cells = <0x0>;
					compatible = "ti,gate-clock";
					clocks = <0xb>;
					ti,bit-shift = <0x8>;
					reg = <0x47c>;
				};

				dpll_core_m4_div2_ck {
					#clock-cells = <0x0>;
					compatible = "fixed-factor-clock";
					clocks = <0xf>;
					clock-mult = <0x1>;
					clock-div = <0x2>;
					linux,phandle = <0x16>;
					phandle = <0x16>;
				};

				ieee5000_fck {
					#clock-cells = <0x0>;
					compatible = "ti,gate-clock";
					clocks = <0x16>;
					ti,bit-shift = <0x1>;
					reg = <0xe4>;
				};

				wdt1_fck {
					#clock-cells = <0x0>;
					compatible = "ti,mux-clock";
					clocks = <0x14 0x12>;
					reg = <0x538>;
				};

				l4_rtc_gclk {
					#clock-cells = <0x0>;
					compatible = "fixed-factor-clock";
					clocks = <0xf>;
					clock-mult = <0x1>;
					clock-div = <0x2>;
				};

				l4hs_gclk {
					#clock-cells = <0x0>;
					compatible = "fixed-factor-clock";
					clocks = <0xf>;
					clock-mult = <0x1>;
					clock-div = <0x1>;
				};

				l3s_gclk {
					#clock-cells = <0x0>;
					compatible = "fixed-factor-clock";
					clocks = <0x16>;
					clock-mult = <0x1>;
					clock-div = <0x1>;
				};

				l4fw_gclk {
					#clock-cells = <0x0>;
					compatible = "fixed-factor-clock";
					clocks = <0x16>;
					clock-mult = <0x1>;
					clock-div = <0x1>;
				};

				l4ls_gclk {
					#clock-cells = <0x0>;
					compatible = "fixed-factor-clock";
					clocks = <0x16>;
					clock-mult = <0x1>;
					clock-div = <0x1>;
				};

				sysclk_div_ck {
					#clock-cells = <0x0>;
					compatible = "fixed-factor-clock";
					clocks = <0xf>;
					clock-mult = <0x1>;
					clock-div = <0x1>;
				};

				cpsw_125mhz_gclk {
					#clock-cells = <0x0>;
					compatible = "fixed-factor-clock";
					clocks = <0x17>;
					clock-mult = <0x1>;
					clock-div = <0x2>;
					linux,phandle = <0x32>;
					phandle = <0x32>;
				};

				cpsw_cpts_rft_clk {
					#clock-cells = <0x0>;
					compatible = "ti,mux-clock";
					clocks = <0x17 0xf>;
					reg = <0x520>;
					linux,phandle = <0x33>;
					phandle = <0x33>;
				};

				gpio0_dbclk_mux_ck {
					#clock-cells = <0x0>;
					compatible = "ti,mux-clock";
					clocks = <0x14 0x15 0x12>;
					reg = <0x53c>;
					linux,phandle = <0x18>;
					phandle = <0x18>;
				};

				gpio0_dbclk {
					#clock-cells = <0x0>;
					compatible = "ti,gate-clock";
					clocks = <0x18>;
					ti,bit-shift = <0x12>;
					reg = <0x408>;
				};

				gpio1_dbclk {
					#clock-cells = <0x0>;
					compatible = "ti,gate-clock";
					clocks = <0x12>;
					ti,bit-shift = <0x12>;
					reg = <0xac>;
				};

				gpio2_dbclk {
					#clock-cells = <0x0>;
					compatible = "ti,gate-clock";
					clocks = <0x12>;
					ti,bit-shift = <0x12>;
					reg = <0xb0>;
				};

				gpio3_dbclk {
					#clock-cells = <0x0>;
					compatible = "ti,gate-clock";
					clocks = <0x12>;
					ti,bit-shift = <0x12>;
					reg = <0xb4>;
				};

				lcd_gclk {
					#clock-cells = <0x0>;
					compatible = "ti,mux-clock";
					clocks = <0x11 0x17 0xc>;
					reg = <0x534>;
					ti,set-rate-parent;
					linux,phandle = <0x1a>;
					phandle = <0x1a>;
				};

				mmc_clk {
					#clock-cells = <0x0>;
					compatible = "fixed-factor-clock";
					clocks = <0xc>;
					clock-mult = <0x1>;
					clock-div = <0x2>;
				};

				gfx_fclk_clksel_ck {
					#clock-cells = <0x0>;
					compatible = "ti,mux-clock";
					clocks = <0xf 0xc>;
					ti,bit-shift = <0x1>;
					reg = <0x52c>;
					linux,phandle = <0x19>;
					phandle = <0x19>;
				};

				gfx_fck_div_ck {
					#clock-cells = <0x0>;
					compatible = "ti,divider-clock";
					clocks = <0x19>;
					reg = <0x52c>;
					ti,max-div = <0x2>;
				};

				sysclkout_pre_ck {
					#clock-cells = <0x0>;
					compatible = "ti,mux-clock";
					clocks = <0x15 0x10 0x9 0xc 0x1a>;
					reg = <0x700>;
					linux,phandle = <0x1b>;
					phandle = <0x1b>;
				};

				clkout2_div_ck {
					#clock-cells = <0x0>;
					compatible = "ti,divider-clock";
					clocks = <0x1b>;
					ti,bit-shift = <0x3>;
					ti,max-div = <0x8>;
					reg = <0x700>;
					linux,phandle = <0x20>;
					phandle = <0x20>;
				};

				dbg_sysclk_ck {
					#clock-cells = <0x0>;
					compatible = "ti,gate-clock";
					clocks = <0x5>;
					ti,bit-shift = <0x13>;
					reg = <0x414>;
					linux,phandle = <0x1c>;
					phandle = <0x1c>;
				};

				dbg_clka_ck {
					#clock-cells = <0x0>;
					compatible = "ti,gate-clock";
					clocks = <0xf>;
					ti,bit-shift = <0x1e>;
					reg = <0x414>;
					linux,phandle = <0x1d>;
					phandle = <0x1d>;
				};

				stm_pmd_clock_mux_ck {
					#clock-cells = <0x0>;
					compatible = "ti,mux-clock";
					clocks = <0x1c 0x1d>;
					ti,bit-shift = <0x16>;
					reg = <0x414>;
					linux,phandle = <0x1e>;
					phandle = <0x1e>;
				};

				trace_pmd_clk_mux_ck {
					#clock-cells = <0x0>;
					compatible = "ti,mux-clock";
					clocks = <0x1c 0x1d>;
					ti,bit-shift = <0x14>;
					reg = <0x414>;
					linux,phandle = <0x1f>;
					phandle = <0x1f>;
				};

				stm_clk_div_ck {
					#clock-cells = <0x0>;
					compatible = "ti,divider-clock";
					clocks = <0x1e>;
					ti,bit-shift = <0x1b>;
					ti,max-div = <0x40>;
					reg = <0x414>;
					ti,index-power-of-two;
				};

				trace_clk_div_ck {
					#clock-cells = <0x0>;
					compatible = "ti,divider-clock";
					clocks = <0x1f>;
					ti,bit-shift = <0x18>;
					ti,max-div = <0x40>;
					reg = <0x414>;
					ti,index-power-of-two;
				};

				clkout2_ck {
					#clock-cells = <0x0>;
					compatible = "ti,gate-clock";
					clocks = <0x20>;
					ti,bit-shift = <0x7>;
					reg = <0x700>;
				};
			};

			clockdomains {

				clk_24mhz_clkdm {
					compatible = "ti,clockdomain";
					clocks = <0x12>;
				};
			};
		};

		scrm@44e10000 {
			compatible = "ti,am3-scrm";
			reg = <0x44e10000 0x2000>;

			clocks {
				#address-cells = <0x1>;
				#size-cells = <0x0>;

				sys_clkin_ck {
					#clock-cells = <0x0>;
					compatible = "ti,mux-clock";
					clocks = <0x21 0x22 0x23 0x24>;
					ti,bit-shift = <0x16>;
					reg = <0x40>;
					linux,phandle = <0x5>;
					phandle = <0x5>;
				};

				adc_tsc_fck {
					#clock-cells = <0x0>;
					compatible = "fixed-factor-clock";
					clocks = <0x5>;
					clock-mult = <0x1>;
					clock-div = <0x1>;
				};

				dcan0_fck {
					#clock-cells = <0x0>;
					compatible = "fixed-factor-clock";
					clocks = <0x5>;
					clock-mult = <0x1>;
					clock-div = <0x1>;
				};

				dcan1_fck {
					#clock-cells = <0x0>;
					compatible = "fixed-factor-clock";
					clocks = <0x5>;
					clock-mult = <0x1>;
					clock-div = <0x1>;
				};

				mcasp0_fck {
					#clock-cells = <0x0>;
					compatible = "fixed-factor-clock";
					clocks = <0x5>;
					clock-mult = <0x1>;
					clock-div = <0x1>;
				};

				mcasp1_fck {
					#clock-cells = <0x0>;
					compatible = "fixed-factor-clock";
					clocks = <0x5>;
					clock-mult = <0x1>;
					clock-div = <0x1>;
				};

				smartreflex0_fck {
					#clock-cells = <0x0>;
					compatible = "fixed-factor-clock";
					clocks = <0x5>;
					clock-mult = <0x1>;
					clock-div = <0x1>;
				};

				smartreflex1_fck {
					#clock-cells = <0x0>;
					compatible = "fixed-factor-clock";
					clocks = <0x5>;
					clock-mult = <0x1>;
					clock-div = <0x1>;
				};

				sha0_fck {
					#clock-cells = <0x0>;
					compatible = "fixed-factor-clock";
					clocks = <0x5>;
					clock-mult = <0x1>;
					clock-div = <0x1>;
				};

				aes0_fck {
					#clock-cells = <0x0>;
					compatible = "fixed-factor-clock";
					clocks = <0x5>;
					clock-mult = <0x1>;
					clock-div = <0x1>;
				};

				rng_fck {
					#clock-cells = <0x0>;
					compatible = "fixed-factor-clock";
					clocks = <0x5>;
					clock-mult = <0x1>;
					clock-div = <0x1>;
				};

				ehrpwm0_tbclk@44e10664 {
					#clock-cells = <0x0>;
					compatible = "ti,gate-clock";
					clocks = <0xc>;
					ti,bit-shift = <0x0>;
					reg = <0x664>;
				};

				ehrpwm1_tbclk@44e10664 {
					#clock-cells = <0x0>;
					compatible = "ti,gate-clock";
					clocks = <0xc>;
					ti,bit-shift = <0x1>;
					reg = <0x664>;
				};

				ehrpwm2_tbclk@44e10664 {
					#clock-cells = <0x0>;
					compatible = "ti,gate-clock";
					clocks = <0xc>;
					ti,bit-shift = <0x2>;
					reg = <0x664>;
				};
			};

			clockdomains {
			};
		};

		syscon@44e10000 {
			compatible = "ti,am33xx-controlmodule", "syscon";
			reg = <0x44e10000 0x800>;
			linux,phandle = <0x34>;
			phandle = <0x34>;
		};

		interrupt-controller@48200000 {
			compatible = "ti,omap2-intc";
			interrupt-controller;
			#interrupt-cells = <0x1>;
			ti,intc-size = <0x80>;
			reg = <0x48200000 0x1000>;
			linux,phandle = <0x1>;
			phandle = <0x1>;
		};

		edma@49000000 {
			compatible = "ti,edma3";
			ti,hwmods = "tpcc", "tptc0", "tptc1", "tptc2";
			reg = <0x49000000 0x10000 0x44e10f90 0x40>;
			interrupts = <0xc 0xd 0xe>;
			#dma-cells = <0x1>;
			linux,phandle = <0x28>;
			phandle = <0x28>;
		};

		gpio@44e07000 {
			compatible = "ti,omap4-gpio";
			ti,hwmods = "gpio1";
			gpio-controller;
			#gpio-cells = <0x2>;
			interrupt-controller;
			#interrupt-cells = <0x2>;
			reg = <0x44e07000 0x1000>;
			interrupts = <0x60>;
			linux,phandle = <0x2b>;
			phandle = <0x2b>;
		};

		gpio@4804c000 {
			compatible = "ti,omap4-gpio";
			ti,hwmods = "gpio2";
			gpio-controller;
			#gpio-cells = <0x2>;
			interrupt-controller;
			#interrupt-cells = <0x2>;
			reg = <0x4804c000 0x1000>;
			interrupts = <0x62>;
			linux,phandle = <0x1ae>;
			phandle = <0x1ae>;
		};

		gpio@481ac000 {
			compatible = "ti,omap4-gpio";
			ti,hwmods = "gpio3";
			gpio-controller;
			#gpio-cells = <0x2>;
			interrupt-controller;
			#interrupt-cells = <0x2>;
			reg = <0x481ac000 0x1000>;
			interrupts = <0x20>;
			linux,phandle = <0x1ad>;
			phandle = <0x1ad>;
		};

		gpio@481ae000 {
			compatible = "ti,omap4-gpio";
			ti,hwmods = "gpio4";
			gpio-controller;
			#gpio-cells = <0x2>;
			interrupt-controller;
			#interrupt-cells = <0x2>;
			reg = <0x481ae000 0x1000>;
			interrupts = <0x3e>;
			linux,phandle = <0x1af>;
			phandle = <0x1af>;
		};

		serial@44e09000 {
			compatible = "ti,omap3-uart";
			ti,hwmods = "uart1";
			clock-frequency = <0x2dc6c00>;
			reg = <0x44e09000 0x2000>;
			interrupts = <0x48>;
			status = "okay";
			pinctrl-names = "default";
			pinctrl-0 = <0x25>;
		};

		serial@48022000 {
			compatible = "ti,omap3-uart";
			ti,hwmods = "uart2";
			clock-frequency = <0x2dc6c00>;
			reg = <0x48022000 0x2000>;
			interrupts = <0x49>;
			status = "disabled";
		};

		serial@48024000 {
			compatible = "ti,omap3-uart";
			ti,hwmods = "uart3";
			clock-frequency = <0x2dc6c00>;
			reg = <0x48024000 0x2000>;
			interrupts = <0x4a>;
			status = "okay";
			pinctrl-names = "default";
			pinctrl-0;
		};

		serial@481a6000 {
			compatible = "ti,omap3-uart";
			ti,hwmods = "uart4";
			clock-frequency = <0x2dc6c00>;
			reg = <0x481a6000 0x2000>;
			interrupts = <0x2c>;
			status = "disabled";
		};

		serial@481a8000 {
			compatible = "ti,omap3-uart";
			ti,hwmods = "uart5";
			clock-frequency = <0x2dc6c00>;
			reg = <0x481a8000 0x2000>;
			interrupts = <0x2d>;
			status = "disabled";
		};

		serial@481aa000 {
			compatible = "ti,omap3-uart";
			ti,hwmods = "uart6";
			clock-frequency = <0x2dc6c00>;
			reg = <0x481aa000 0x2000>;
			interrupts = <0x2e>;
			status = "disabled";
		};

		i2c@44e0b000 {
			compatible = "ti,omap4-i2c";
			#address-cells = <0x1>;
			#size-cells = <0x0>;
			ti,hwmods = "i2c1";
			reg = <0x44e0b000 0x1000>;
			interrupts = <0x46>;
			status = "okay";
			pinctrl-names = "default";
			pinctrl-0 = <0x26>;
			clock-frequency = <0x61a80>;
			linux,phandle = <0x1b2>;
			phandle = <0x1b2>;

			tps@24 {
				reg = <0x24>;
				compatible = "ti,tps65217";
				ti,pmic-shutdown-controller;

				regulators {
					#address-cells = <0x1>;
					#size-cells = <0x0>;

					regulator@0 {
						reg = <0x0>;
						regulator-compatible = "dcdc1";
						regulator-always-on;
						regulator-name = "vdd_ddr3";
						regulator-min-microvolt = <0x149970>;
						regulator-max-microvolt = <0x149970>;
						regulator-boot-on;
					};

					regulator@1 {
						reg = <0x1>;
						regulator-compatible = "dcdc2";
						regulator-name = "vdd_mpu";
						regulator-min-microvolt = <0xdec74>;
						regulator-max-microvolt = <0x1506d0>;
						regulator-boot-on;
						regulator-always-on;
						linux,phandle = <0x3>;
						phandle = <0x3>;
					};

					regulator@2 {
						reg = <0x2>;
						regulator-compatible = "dcdc3";
						regulator-name = "vdd_core";
						regulator-min-microvolt = <0xe1d48>;
						regulator-max-microvolt = <0x118c30>;
						regulator-boot-on;
						regulator-always-on;
					};

					regulator@3 {
						reg = <0x3>;
						regulator-compatible = "ldo1";
						regulator-always-on;
					};

					regulator@4 {
						reg = <0x4>;
						regulator-compatible = "ldo2";
						regulator-always-on;
					};

					regulator@5 {
						reg = <0x5>;
						regulator-compatible = "ldo3";
						regulator-always-on;
						regulator-min-microvolt = <0x1b7740>;
						regulator-max-microvolt = <0x1b7740>;
					};

					regulator@6 {
						reg = <0x6>;
						regulator-compatible = "ldo4";
						regulator-always-on;
					};
				};
			};

			baseboard_eeprom@50 {
				compatible = "at,24c256";
				reg = <0x50>;
			};
		};

		i2c@4802a000 {
			compatible = "ti,omap4-i2c";
			#address-cells = <0x1>;
			#size-cells = <0x0>;
			ti,hwmods = "i2c2";
			reg = <0x4802a000 0x1000>;
			interrupts = <0x47>;
			status = "disabled";
		};

		i2c@4819c000 {
			compatible = "ti,omap4-i2c";
			#address-cells = <0x1>;
			#size-cells = <0x0>;
			ti,hwmods = "i2c3";
			reg = <0x4819c000 0x1000>;
			interrupts = <0x1e>;
			status = "okay";
			pinctrl-names = "default";
			pinctrl-0 = <0x27>;
			clock-frequency = <0x186a0>;

			cape_eeprom0@54 {
				compatible = "at,24c256";
				reg = <0x54>;
			};

			cape_eeprom1@55 {
				compatible = "at,24c256";
				reg = <0x55>;
			};

			cape_eeprom2@56 {
				compatible = "at,24c256";
				reg = <0x56>;
			};

			cape_eeprom3@57 {
				compatible = "at,24c256";
				reg = <0x57>;
			};
		};

		mmc@48060000 {
			compatible = "ti,omap4-hsmmc";
			ti,hwmods = "mmc1";
			ti,dual-volt;
			ti,needs-special-reset;
			ti,needs-special-hs-handling;
			dmas = <0x28 0x18 0x28 0x19>;
			dma-names = "tx", "rx";
			interrupts = <0x40>;
			interrupt-parent = <0x1>;
			reg = <0x48060000 0x1000>;
			status = "okay";
			bus-width = <0x4>;
			pinctrl-names = "default", "sleep";
			pinctrl-0 = <0x29>;
			pinctrl-1 = <0x2a>;
			cd-gpios = <0x2b 0x6 0x0>;
			cd-inverted;
			vmmc-supply = <0x2c>;
		};

		mmc@481d8000 {
			compatible = "ti,omap4-hsmmc";
			ti,hwmods = "mmc2";
			ti,needs-special-reset;
			dmas = <0x28 0x2 0x28 0x3>;
			dma-names = "tx", "rx";
			interrupts = <0x1c>;
			interrupt-parent = <0x1>;
			reg = <0x481d8000 0x1000>;
			status = "okay";
			vmmc-supply = <0x2c>;
			pinctrl-names = "default";
			pinctrl-0 = <0x2d>;
			bus-width = <0x8>;
			ti,vcc-aux-disable-is-sleep;
		};

		mmc@47810000 {
			compatible = "ti,omap4-hsmmc";
			ti,hwmods = "mmc3";
			ti,needs-special-reset;
			interrupts = <0x1d>;
			interrupt-parent = <0x1>;
			reg = <0x47810000 0x1000>;
			status = "disabled";
		};

		spinlock@480ca000 {
			compatible = "ti,omap4-hwspinlock";
			reg = <0x480ca000 0x1000>;
			ti,hwmods = "spinlock";
			#hwlock-cells = <0x1>;
		};

		wdt@44e35000 {
			compatible = "ti,omap3-wdt";
			ti,hwmods = "wd_timer2";
			reg = <0x44e35000 0x1000>;
			interrupts = <0x5b>;
		};

		d_can@481cc000 {
			compatible = "bosch,d_can";
			ti,hwmods = "d_can0";
			reg = <0x481cc000 0x2000 0x44e10644 0x4>;
			interrupts = <0x34>;
			status = "disabled";
		};

		d_can@481d0000 {
			compatible = "bosch,d_can";
			ti,hwmods = "d_can1";
			reg = <0x481d0000 0x2000 0x44e10644 0x4>;
			interrupts = <0x37>;
			status = "disabled";
		};

		mailbox@480C8000 {
			compatible = "ti,omap4-mailbox";
			reg = <0x480c8000 0x200>;
			interrupts = <0x4d>;
			ti,hwmods = "mailbox";
			#mbox-cells = <0x1>;
			ti,mbox-num-users = <0x4>;
			ti,mbox-num-fifos = <0x8>;
			linux,phandle = <0x3a>;
			phandle = <0x3a>;

			wkup_m3 {
				ti,mbox-tx = <0x0 0x0 0x0>;
				ti,mbox-rx = <0x0 0x0 0x3>;
				linux,phandle = <0x3b>;
				phandle = <0x3b>;
			};

			mbox_pru0 {
				ti,mbox-tx = <0x2 0x0 0x0>;
				ti,mbox-rx = <0x3 0x0 0x0>;
				linux,phandle = <0x3c>;
				phandle = <0x3c>;
			};

			mbox_pru1 {
				ti,mbox-tx = <0x4 0x0 0x0>;
				ti,mbox-rx = <0x5 0x0 0x0>;
				linux,phandle = <0x3d>;
				phandle = <0x3d>;
			};
		};

		timer@44e31000 {
			compatible = "ti,am335x-timer-1ms";
			reg = <0x44e31000 0x400>;
			interrupts = <0x43>;
			ti,hwmods = "timer1";
			ti,timer-alwon;
		};

		timer@48040000 {
			compatible = "ti,am335x-timer";
			reg = <0x48040000 0x400>;
			interrupts = <0x44>;
			ti,hwmods = "timer2";
		};

		timer@48042000 {
			compatible = "ti,am335x-timer";
			reg = <0x48042000 0x400>;
			interrupts = <0x45>;
			ti,hwmods = "timer3";
		};

		timer@48044000 {
			compatible = "ti,am335x-timer";
			reg = <0x48044000 0x400>;
			interrupts = <0x5c>;
			ti,hwmods = "timer4";
			ti,timer-pwm;
		};

		timer@48046000 {
			compatible = "ti,am335x-timer";
			reg = <0x48046000 0x400>;
			interrupts = <0x5d>;
			ti,hwmods = "timer5";
			ti,timer-pwm;
		};

		timer@48048000 {
			compatible = "ti,am335x-timer";
			reg = <0x48048000 0x400>;
			interrupts = <0x5e>;
			ti,hwmods = "timer6";
			ti,timer-pwm;
		};

		timer@4804a000 {
			compatible = "ti,am335x-timer";
			reg = <0x4804a000 0x400>;
			interrupts = <0x5f>;
			ti,hwmods = "timer7";
			ti,timer-pwm;
		};

		rtc@44e3e000 {
			compatible = "ti,am3352-rtc";
			reg = <0x44e3e000 0x1000>;
			interrupts = <0x4b 0x4c>;
			ti,hwmods = "rtc";
			ti,system-power-controller;
		};

		spi@48030000 {
			compatible = "ti,omap4-mcspi";
			#address-cells = <0x1>;
			#size-cells = <0x0>;
			reg = <0x48030000 0x400>;
			interrupts = <0x41>;
			ti,spi-num-cs = <0x2>;
			ti,hwmods = "spi0";
			dmas = <0x28 0x10 0x28 0x11 0x28 0x12 0x28 0x13>;
			dma-names = "tx0", "rx0", "tx1", "rx1";
			status = "disabled";
		};

		spi@481a0000 {
			compatible = "ti,omap4-mcspi";
			#address-cells = <0x1>;
			#size-cells = <0x0>;
			reg = <0x481a0000 0x400>;
			interrupts = <0x7d>;
			ti,spi-num-cs = <0x2>;
			ti,hwmods = "spi1";
			dmas = <0x28 0x2a 0x28 0x2b 0x28 0x2c 0x28 0x2d>;
			dma-names = "tx0", "rx0", "tx1", "rx1";
			status = "disabled";
		};

		usb@47400000 {
			compatible = "ti,am33xx-usb";
			reg = <0x47400000 0x1000>;
			ranges;
			#address-cells = <0x1>;
			#size-cells = <0x1>;
			ti,hwmods = "usb_otg_hs";
			status = "okay";

			control@44e10620 {
				compatible = "ti,am335x-usb-ctrl-module";
				reg = <0x44e10620 0x10 0x44e10648 0x4>;
				reg-names = "phy_ctrl", "wakeup";
				status = "okay";
				linux,phandle = <0x2e>;
				phandle = <0x2e>;
			};

			usb-phy@47401300 {
				compatible = "ti,am335x-usb-phy";
				reg = <0x47401300 0x100>;
				reg-names = "phy";
				status = "okay";
				ti,ctrl_mod = <0x2e>;
				linux,phandle = <0x2f>;
				phandle = <0x2f>;
			};

			usb@47401000 {
				compatible = "ti,musb-am33xx";
				status = "okay";
				reg = <0x47401400 0x400 0x47401000 0x200>;
				reg-names = "mc", "control";
				interrupts = <0x12>;
				interrupt-names = "mc";
				dr_mode = "otg";
				mentor,multipoint = <0x1>;
				mentor,num-eps = <0x10>;
				mentor,ram-bits = <0xc>;
				mentor,power = <0x1f4>;
				phys = <0x2f>;
				dmas = <0x30 0x0 0x0 0x30 0x1 0x0 0x30 0x2 0x0 0x30 0x3 0x0 0x30 0x4 0x0 0x30 0x5 0x0 0x30 0x6 0x0 0x30 0x7 0x0 0x30 0x8 0x0 0x30 0x9 0x0 0x30 0xa 0x0 0x30 0xb 0x0 0x30 0xc 0x0 0x30 0xd 0x0 0x30 0xe 0x0 0x30 0x0 0x1 0x30 0x1 0x1 0x30 0x2 0x1 0x30 0x3 0x1 0x30 0x4 0x1 0x30 0x5 0x1 0x30 0x6 0x1 0x30 0x7 0x1 0x30 0x8 0x1 0x30 0x9 0x1 0x30 0xa 0x1 0x30 0xb 0x1 0x30 0xc 0x1 0x30 0xd 0x1 0x30 0xe 0x1>;
				dma-names = "rx1", "rx2", "rx3", "rx4", "rx5", "rx6", "rx7", "rx8", "rx9", "rx10", "rx11", "rx12", "rx13", "rx14", "rx15", "tx1", "tx2", "tx3", "tx4", "tx5", "tx6", "tx7", "tx8", "tx9", "tx10", "tx11", "tx12", "tx13", "tx14", "tx15";
			};

			usb-phy@47401b00 {
				compatible = "ti,am335x-usb-phy";
				reg = <0x47401b00 0x100>;
				reg-names = "phy";
				status = "okay";
				ti,ctrl_mod = <0x2e>;
				linux,phandle = <0x31>;
				phandle = <0x31>;
			};

			usb@47401800 {
				compatible = "ti,musb-am33xx";
				status = "okay";
				reg = <0x47401c00 0x400 0x47401800 0x200>;
				reg-names = "mc", "control";
				interrupts = <0x13>;
				interrupt-names = "mc";
				dr_mode = "host";
				mentor,multipoint = <0x1>;
				mentor,num-eps = <0x10>;
				mentor,ram-bits = <0xc>;
				mentor,power = <0x1f4>;
				phys = <0x31>;
				dmas = <0x30 0xf 0x0 0x30 0x10 0x0 0x30 0x11 0x0 0x30 0x12 0x0 0x30 0x13 0x0 0x30 0x14 0x0 0x30 0x15 0x0 0x30 0x16 0x0 0x30 0x17 0x0 0x30 0x18 0x0 0x30 0x19 0x0 0x30 0x1a 0x0 0x30 0x1b 0x0 0x30 0x1c 0x0 0x30 0x1d 0x0 0x30 0xf 0x1 0x30 0x10 0x1 0x30 0x11 0x1 0x30 0x12 0x1 0x30 0x13 0x1 0x30 0x14 0x1 0x30 0x15 0x1 0x30 0x16 0x1 0x30 0x17 0x1 0x30 0x18 0x1 0x30 0x19 0x1 0x30 0x1a 0x1 0x30 0x1b 0x1 0x30 0x1c 0x1 0x30 0x1d 0x1>;
				dma-names = "rx1", "rx2", "rx3", "rx4", "rx5", "rx6", "rx7", "rx8", "rx9", "rx10", "rx11", "rx12", "rx13", "rx14", "rx15", "tx1", "tx2", "tx3", "tx4", "tx5", "tx6", "tx7", "tx8", "tx9", "tx10", "tx11", "tx12", "tx13", "tx14", "tx15";
			};

			dma-controller@47402000 {
				compatible = "ti,am3359-cppi41";
				reg = <0x47400000 0x1000 0x47402000 0x1000 0x47403000 0x1000 0x47404000 0x4000>;
				reg-names = "glue", "controller", "scheduler", "queuemgr";
				interrupts = <0x11>;
				interrupt-names = "glue";
				#dma-cells = <0x2>;
				#dma-channels = <0x1e>;
				#dma-requests = <0x100>;
				status = "okay";
				linux,phandle = <0x30>;
				phandle = <0x30>;
			};
		};

		epwmss@48300000 {
			compatible = "ti,am33xx-pwmss";
			reg = <0x48300000 0x10>;
			ti,hwmods = "epwmss0";
			#address-cells = <0x1>;
			#size-cells = <0x1>;
			status = "disabled";
			ranges = <0x48300100 0x48300100 0x80 0x48300180 0x48300180 0x80 0x48300200 0x48300200 0x80>;

			ecap@48300100 {
				compatible = "ti,am33xx-ecap";
				#pwm-cells = <0x3>;
				reg = <0x48300100 0x80>;
				ti,hwmods = "ecap0";
				status = "disabled";
			};

			ehrpwm@48300200 {
				compatible = "ti,am33xx-ehrpwm";
				#pwm-cells = <0x3>;
				reg = <0x48300200 0x80>;
				ti,hwmods = "ehrpwm0";
				status = "disabled";
			};
		};

		epwmss@48302000 {
			compatible = "ti,am33xx-pwmss";
			reg = <0x48302000 0x10>;
			ti,hwmods = "epwmss1";
			#address-cells = <0x1>;
			#size-cells = <0x1>;
			status = "disabled";
			ranges = <0x48302100 0x48302100 0x80 0x48302180 0x48302180 0x80 0x48302200 0x48302200 0x80>;

			ecap@48302100 {
				compatible = "ti,am33xx-ecap";
				#pwm-cells = <0x3>;
				reg = <0x48302100 0x80>;
				ti,hwmods = "ecap1";
				status = "disabled";
			};

			ehrpwm@48302200 {
				compatible = "ti,am33xx-ehrpwm";
				#pwm-cells = <0x3>;
				reg = <0x48302200 0x80>;
				ti,hwmods = "ehrpwm1";
				status = "disabled";
			};
		};

		epwmss@48304000 {
			compatible = "ti,am33xx-pwmss";
			reg = <0x48304000 0x10>;
			ti,hwmods = "epwmss2";
			#address-cells = <0x1>;
			#size-cells = <0x1>;
			status = "disabled";
			ranges = <0x48304100 0x48304100 0x80 0x48304180 0x48304180 0x80 0x48304200 0x48304200 0x80>;

			ecap@48304100 {
				compatible = "ti,am33xx-ecap";
				#pwm-cells = <0x3>;
				reg = <0x48304100 0x80>;
				ti,hwmods = "ecap2";
				status = "disabled";
			};

			ehrpwm@48304200 {
				compatible = "ti,am33xx-ehrpwm";
				#pwm-cells = <0x3>;
				reg = <0x48304200 0x80>;
				ti,hwmods = "ehrpwm2";
				status = "disabled";
			};
		};

		ethernet@4a100000 {
			compatible = "ti,cpsw";
			ti,hwmods = "cpgmac0";
			clocks = <0x32 0x33>;
			clock-names = "fck", "cpts";
			cpdma_channels = <0x8>;
			ale_entries = <0x400>;
			bd_ram_size = <0x2000>;
			no_bd_ram = <0x0>;
			rx_descs = <0x40>;
			mac_control = <0x20>;
			slaves = <0x2>;
			active_slave = <0x0>;
			cpts_clock_mult = <0x80000000>;
			cpts_clock_shift = <0x1d>;
			reg = <0x4a100000 0x800 0x4a101200 0x100>;
			#address-cells = <0x1>;
			#size-cells = <0x1>;
			interrupt-parent = <0x1>;
			interrupts = <0x28 0x29 0x2a 0x2b>;
			ranges;
			syscon = <0x34>;
			pinctrl-names = "default", "sleep";
			pinctrl-0 = <0x35>;
			pinctrl-1 = <0x36>;

			mdio@4a101000 {
				compatible = "ti,davinci_mdio";
				#address-cells = <0x1>;
				#size-cells = <0x0>;
				ti,hwmods = "davinci_mdio";
				bus_freq = <0xf4240>;
				reg = <0x4a101000 0x100>;
				pinctrl-names = "default", "sleep";
				pinctrl-0 = <0x37>;
				pinctrl-1 = <0x38>;
				linux,phandle = <0x39>;
				phandle = <0x39>;
			};

			slave@4a100200 {
				mac-address = [00 00 00 00 00 00];
				phy_id = <0x39 0x0>;
				phy-mode = "mii";
			};

			slave@4a100300 {
				mac-address = [00 00 00 00 00 00];
				phy_id = <0x39 0x1>;
				phy-mode = "mii";
			};

			cpsw-phy-sel@44e10650 {
				compatible = "ti,am3352-cpsw-phy-sel";
				reg = <0x44e10650 0x4>;
				reg-names = "gmii-sel";
			};
		};

		ocmcram@40300000 {
			compatible = "ti,am3352-ocmcram";
			reg = <0x40300000 0x10000>;
			ti,hwmods = "ocmcram";
		};

		wkup_m3@44d00000 {
			compatible = "ti,am3353-wkup-m3";
			reg = <0x44d00000 0x4000 0x44d80000 0x2000 0x44e11324 0x24>;
			reg-names = "m3_umem", "m3_dmem", "ipc_regs";
			interrupts = <0x4e>;
			ti,hwmods = "wkup_m3";
			ti,no-reset-on-init;
			mboxes = <0x3a 0x3b>;
			ti,scale-data-fw = "am335x-bone-scale-data.bin";
		};

		pruss@4a300000 {
			compatible = "ti,am335x-pruss";
			ti,hwmods = "pruss";
			reg = <0x4a300000 0x2000 0x4a302000 0x2000 0x4a310000 0x3000 0x4a320000 0x2000 0x4a326000 0x2000>;
			reg-names = "dram0", "dram1", "shrdram2", "intc", "cfg";
			interrupts = <0x14 0x15 0x16 0x17 0x18 0x19 0x1a 0x1b>;
			#address-cells = <0x1>;
			#size-cells = <0x1>;
			ranges;

			pru@4a334000 {
				compatible = "ti,pru-rproc";
				reg = <0x4a334000 0x2000 0x4a322000 0x400 0x4a322400 0x100>;
				reg-names = "iram", "control", "debug";
				mboxes = <0x3a 0x3c>;
			};

			pru@4a338000 {
				compatible = "ti,pru-rproc";
				reg = <0x4a338000 0x2000 0x4a324000 0x400 0x4a324400 0x100>;
				reg-names = "iram", "control", "debug";
				mboxes = <0x3a 0x3d>;
			};
		};

		elm@48080000 {
			compatible = "ti,am3352-elm";
			reg = <0x48080000 0x2000>;
			interrupts = <0x4>;
			ti,hwmods = "elm";
			status = "disabled";
		};

		lcdc@4830e000 {
			compatible = "ti,am33xx-tilcdc";
			reg = <0x4830e000 0x1000>;
			interrupt-parent = <0x1>;
			interrupts = <0x24>;
			ti,hwmods = "lcdc";
			status = "okay";
		};

		tscadc@44e0d000 {
			compatible = "ti,am3359-tscadc";
			reg = <0x44e0d000 0x1000>;
			interrupt-parent = <0x1>;
			interrupts = <0x10>;
			ti,hwmods = "adc_tsc";
			status = "disabled";

			tsc {
				compatible = "ti,am3359-tsc";
			};

			adc {
				#io-channel-cells = <0x1>;
				compatible = "ti,am3359-adc";
			};
		};

		gpmc@50000000 {
			compatible = "ti,am3352-gpmc";
			ti,hwmods = "gpmc";
			ti,no-idle-on-init;
			reg = <0x50000000 0x2000>;
			interrupts = <0x64>;
			gpmc,num-cs = <0x7>;
			gpmc,num-waitpins = <0x2>;
			#address-cells = <0x2>;
			#size-cells = <0x1>;
			status = "disabled";
		};

		sham@53100000 {
			compatible = "ti,omap4-sham";
			ti,hwmods = "sham";
			reg = <0x53100000 0x200>;
			interrupts = <0x6d>;
			dmas = <0x28 0x24>;
			dma-names = "rx";
		};

		aes@53500000 {
			compatible = "ti,omap4-aes";
			ti,hwmods = "aes";
			reg = <0x53500000 0xa0>;
			interrupts = <0x67>;
			dmas = <0x28 0x6 0x28 0x5>;
			dma-names = "tx", "rx";
		};

		mcasp@48038000 {
			compatible = "ti,am33xx-mcasp-audio";
			ti,hwmods = "mcasp0";
			reg = <0x48038000 0x2000 0x46000000 0x400000>;
			reg-names = "mpu", "dat";
			interrupts = <0x50 0x51>;
			interrupts-names = "tx", "rx";
			status = "okay";
			dmas = <0x28 0x8 0x28 0x9>;
			dma-names = "tx", "rx";
			pinctrl-names = "default", "sleep";
			pinctrl-0 = <0x3e>;
			op-mode = <0x0>;
			tdm-slots = <0x2>;
			serial-dir = <0x0 0x0 0x1 0x0>;
			tx-num-evt = <0x1>;
			rx-num-evt = <0x1>;
			linux,phandle = <0x1b6>;
			phandle = <0x1b6>;
		};

		mcasp@4803C000 {
			compatible = "ti,am33xx-mcasp-audio";
			ti,hwmods = "mcasp1";
			reg = <0x4803c000 0x2000 0x46400000 0x400000>;
			reg-names = "mpu", "dat";
			interrupts = <0x52 0x53>;
			interrupts-names = "tx", "rx";
			status = "disabled";
			dmas = <0x28 0xa 0x28 0xb>;
			dma-names = "tx", "rx";
		};

		rng@48310000 {
			compatible = "ti,omap4-rng";
			ti,hwmods = "rng";
			reg = <0x48310000 0x2000>;
			interrupts = <0x6f>;
		};

		sgx@0x56000000 {
			compatible = "ti,sgx";
			ti,hwmods = "gfx";
			reg = <0x56000000 0x1000000>;
			interrupts = <0x25>;
		};

		P8_07_pinmux {
			compatible = "bone-pinmux-helper";
			status = "okay";
			pinctrl-names = "default", "gpio", "gpio_pu", "gpio_pd", "timer";
			pinctrl-0 = <0x3f>;
			pinctrl-1 = <0x40>;
			pinctrl-2 = <0x41>;
			pinctrl-3 = <0x42>;
			pinctrl-4 = <0x43>;
		};

		P8_08_pinmux {
			compatible = "bone-pinmux-helper";
			status = "okay";
			pinctrl-names = "default", "gpio", "gpio_pu", "gpio_pd", "timer";
			pinctrl-0 = <0x44>;
			pinctrl-1 = <0x45>;
			pinctrl-2 = <0x46>;
			pinctrl-3 = <0x47>;
			pinctrl-4 = <0x48>;
		};

		P8_09_pinmux {
			compatible = "bone-pinmux-helper";
			status = "okay";
			pinctrl-names = "default", "gpio", "gpio_pu", "gpio_pd", "timer";
			pinctrl-0 = <0x49>;
			pinctrl-1 = <0x4a>;
			pinctrl-2 = <0x4b>;
			pinctrl-3 = <0x4c>;
			pinctrl-4 = <0x4d>;
		};

		P8_10_pinmux {
			compatible = "bone-pinmux-helper";
			status = "okay";
			pinctrl-names = "default", "gpio", "gpio_pu", "gpio_pd", "timer";
			pinctrl-0 = <0x4e>;
			pinctrl-1 = <0x4f>;
			pinctrl-2 = <0x50>;
			pinctrl-3 = <0x51>;
			pinctrl-4 = <0x52>;
		};

		P8_11_pinmux {
			compatible = "bone-pinmux-helper";
			status = "okay";
			pinctrl-names = "default", "gpio", "gpio_pu", "gpio_pd", "pruout", "qep";
			pinctrl-0 = <0x53>;
			pinctrl-1 = <0x54>;
			pinctrl-2 = <0x55>;
			pinctrl-3 = <0x56>;
			pinctrl-4 = <0x57>;
			pinctrl-5 = <0x58>;
		};

		P8_12_pinmux {
			compatible = "bone-pinmux-helper";
			status = "okay";
			pinctrl-names = "default", "gpio", "gpio_pu", "gpio_pd", "pruout", "qep";
			pinctrl-0 = <0x59>;
			pinctrl-1 = <0x5a>;
			pinctrl-2 = <0x5b>;
			pinctrl-3 = <0x5c>;
			pinctrl-4 = <0x5d>;
			pinctrl-5 = <0x5e>;
		};

		P8_13_pinmux {
			compatible = "bone-pinmux-helper";
			status = "okay";
			pinctrl-names = "default", "gpio", "gpio_pu", "gpio_pd", "pwm";
			pinctrl-0 = <0x5f>;
			pinctrl-1 = <0x60>;
			pinctrl-2 = <0x61>;
			pinctrl-3 = <0x62>;
			pinctrl-4 = <0x63>;
		};

		P8_14_pinmux {
			compatible = "bone-pinmux-helper";
			status = "okay";
			pinctrl-names = "default", "gpio", "gpio_pu", "gpio_pd", "pwm";
			pinctrl-0 = <0x64>;
			pinctrl-1 = <0x65>;
			pinctrl-2 = <0x66>;
			pinctrl-3 = <0x67>;
			pinctrl-4 = <0x68>;
		};

		P8_15_pinmux {
			compatible = "bone-pinmux-helper";
			status = "okay";
			pinctrl-names = "default", "gpio", "gpio_pu", "gpio_pd", "pruin", "qep";
			pinctrl-0 = <0x69>;
			pinctrl-1 = <0x6a>;
			pinctrl-2 = <0x6b>;
			pinctrl-3 = <0x6c>;
			pinctrl-4 = <0x6d>;
			pinctrl-5 = <0x6e>;
		};

		P8_16_pinmux {
			compatible = "bone-pinmux-helper";
			status = "okay";
			pinctrl-names = "default", "gpio", "gpio_pu", "gpio_pd", "pruin", "qep";
			pinctrl-0 = <0x6f>;
			pinctrl-1 = <0x70>;
			pinctrl-2 = <0x71>;
			pinctrl-3 = <0x72>;
			pinctrl-4 = <0x73>;
			pinctrl-5 = <0x74>;
		};

		P8_17_pinmux {
			compatible = "bone-pinmux-helper";
			status = "okay";
			pinctrl-names = "default", "gpio", "gpio_pu", "gpio_pd", "pwm";
			pinctrl-0 = <0x75>;
			pinctrl-1 = <0x76>;
			pinctrl-2 = <0x77>;
			pinctrl-3 = <0x78>;
			pinctrl-4 = <0x79>;
		};

		P8_18_pinmux {
			compatible = "bone-pinmux-helper";
			status = "okay";
			pinctrl-names = "default", "gpio";
			pinctrl-0 = <0x7a>;
			pinctrl-1 = <0x7b>;
			pinctrl-2 = <0x7c>;
			pinctrl-3 = <0x7d>;
		};

		P8_19_pinmux {
			compatible = "bone-pinmux-helper";
			status = "okay";
			pinctrl-names = "default", "gpio", "gpio_pu", "gpio_pd", "pwm";
			pinctrl-0 = <0x7e>;
			pinctrl-1 = <0x7f>;
			pinctrl-2 = <0x80>;
			pinctrl-3 = <0x81>;
			pinctrl-4 = <0x82>;
		};

		P8_26_pinmux {
			compatible = "bone-pinmux-helper";
			status = "okay";
			pinctrl-names = "default", "gpio";
			pinctrl-0 = <0x83>;
			pinctrl-1 = <0x84>;
			pinctrl-2 = <0x85>;
			pinctrl-3 = <0x86>;
		};

		P8_27_pinmux {
			compatible = "bone-pinmux-helper";
			status = "okay";
			pinctrl-names = "default", "gpio", "gpio_pu", "gpio_pd", "pruout", "pruin", "hdmi";
			pinctrl-0 = <0x87>;
			pinctrl-1 = <0x88>;
			pinctrl-2 = <0x89>;
			pinctrl-3 = <0x8a>;
			pinctrl-4 = <0x8b>;
			pinctrl-5 = <0x8c>;
			pinctrl-6 = <0x8d>;
			mode = "hdmi";
		};

		P8_28_pinmux {
			compatible = "bone-pinmux-helper";
			status = "okay";
			pinctrl-names = "default", "gpio", "gpio_pu", "gpio_pd", "pruout", "pruin", "hdmi";
			pinctrl-0 = <0x8e>;
			pinctrl-1 = <0x8f>;
			pinctrl-2 = <0x90>;
			pinctrl-3 = <0x91>;
			pinctrl-4 = <0x92>;
			pinctrl-5 = <0x93>;
			pinctrl-6 = <0x94>;
			mode = "hdmi";
		};

		P8_29_pinmux {
			compatible = "bone-pinmux-helper";
			status = "okay";
			pinctrl-names = "default", "gpio", "gpio_pu", "gpio_pd", "pruout", "pruin", "hdmi";
			pinctrl-0 = <0x95>;
			pinctrl-1 = <0x96>;
			pinctrl-2 = <0x97>;
			pinctrl-3 = <0x98>;
			pinctrl-4 = <0x99>;
			pinctrl-5 = <0x9a>;
			pinctrl-6 = <0x9b>;
			mode = "hdmi";
		};

		P8_30_pinmux {
			compatible = "bone-pinmux-helper";
			status = "okay";
			pinctrl-names = "default", "gpio", "gpio_pu", "gpio_pd", "pruout", "pruin", "hdmi";
			pinctrl-0 = <0x9c>;
			pinctrl-1 = <0x9d>;
			pinctrl-2 = <0x9e>;
			pinctrl-3 = <0x9f>;
			pinctrl-4 = <0xa0>;
			pinctrl-5 = <0xa1>;
			pinctrl-6 = <0xa2>;
			mode = "hdmi";
		};

		P8_31_pinmux {
			compatible = "bone-pinmux-helper";
			status = "okay";
			pinctrl-names = "default", "gpio", "gpio_pu", "gpio_pd", "uart", "hdmi";
			pinctrl-0 = <0xa3>;
			pinctrl-1 = <0xa4>;
			pinctrl-2 = <0xa5>;
			pinctrl-3 = <0xa6>;
			pinctrl-4 = <0xa7>;
			pinctrl-5 = <0xa8>;
			mode = "hdmi";
		};

		P8_32_pinmux {
			compatible = "bone-pinmux-helper";
			status = "okay";
			pinctrl-names = "default", "gpio", "gpio_pu", "gpio_pd", "hdmi";
			pinctrl-0 = <0xa9>;
			pinctrl-1 = <0xaa>;
			pinctrl-2 = <0xab>;
			pinctrl-3 = <0xac>;
			pinctrl-4 = <0xad>;
			mode = "hdmi";
		};

		P8_33_pinmux {
			compatible = "bone-pinmux-helper";
			status = "okay";
			pinctrl-names = "default", "gpio", "gpio_pu", "gpio_pd", "hdmi";
			pinctrl-0 = <0xae>;
			pinctrl-1 = <0xaf>;
			pinctrl-2 = <0xb0>;
			pinctrl-3 = <0xb1>;
			pinctrl-4 = <0xb2>;
			mode = "hdmi";
		};

		P8_34_pinmux {
			compatible = "bone-pinmux-helper";
			status = "okay";
			pinctrl-names = "default", "gpio", "gpio_pu", "gpio_pd", "pwm", "hdmi";
			pinctrl-0 = <0xb3>;
			pinctrl-1 = <0xb4>;
			pinctrl-2 = <0xb5>;
			pinctrl-3 = <0xb6>;
			pinctrl-4 = <0xb7>;
			pinctrl-5 = <0xb8>;
			mode = "hdmi";
		};

		P8_35_pinmux {
			compatible = "bone-pinmux-helper";
			status = "okay";
			pinctrl-names = "default", "gpio", "gpio_pu", "gpio_pd", "hdmi";
			pinctrl-0 = <0xb9>;
			pinctrl-1 = <0xba>;
			pinctrl-2 = <0xbb>;
			pinctrl-3 = <0xbc>;
			pinctrl-4 = <0xbd>;
			mode = "hdmi";
		};

		P8_36_pinmux {
			compatible = "bone-pinmux-helper";
			status = "okay";
			pinctrl-names = "default", "gpio", "gpio_pu", "gpio_pd", "pwm", "hdmi";
			pinctrl-0 = <0xbe>;
			pinctrl-1 = <0xbf>;
			pinctrl-2 = <0xc0>;
			pinctrl-3 = <0xc1>;
			pinctrl-4 = <0xc2>;
			pinctrl-5 = <0xc3>;
			mode = "hdmi";
		};

		P8_37_pinmux {
			compatible = "bone-pinmux-helper";
			status = "okay";
			pinctrl-names = "default", "gpio", "gpio_pu", "gpio_pd", "uart", "pwm", "hdmi";
			pinctrl-0 = <0xc4>;
			pinctrl-1 = <0xc5>;
			pinctrl-2 = <0xc6>;
			pinctrl-3 = <0xc7>;
			pinctrl-4 = <0xc8>;
			pinctrl-5 = <0xc9>;
			pinctrl-6 = <0xca>;
			mode = "hdmi";
		};

		P8_38_pinmux {
			compatible = "bone-pinmux-helper";
			status = "okay";
			pinctrl-names = "default", "gpio", "gpio_pu", "gpio_pd", "uart", "pwm", "hdmi";
			pinctrl-0 = <0xcb>;
			pinctrl-1 = <0xcc>;
			pinctrl-2 = <0xcd>;
			pinctrl-3 = <0xce>;
			pinctrl-4 = <0xcf>;
			pinctrl-5 = <0xd0>;
			pinctrl-6 = <0xd1>;
			mode = "hdmi";
		};

		P8_39_pinmux {
			compatible = "bone-pinmux-helper";
			status = "okay";
			pinctrl-names = "default", "gpio", "gpio_pu", "gpio_pd", "pruout", "pruin", "hdmi";
			pinctrl-0 = <0xd2>;
			pinctrl-1 = <0xd3>;
			pinctrl-2 = <0xd4>;
			pinctrl-3 = <0xd5>;
			pinctrl-4 = <0xd6>;
			pinctrl-5 = <0xd7>;
			pinctrl-6 = <0xd8>;
			mode = "hdmi";
		};

		P8_40_pinmux {
			compatible = "bone-pinmux-helper";
			status = "okay";
			pinctrl-names = "default", "gpio", "gpio_pu", "gpio_pd", "pruout", "pruin", "hdmi";
			pinctrl-0 = <0xd9>;
			pinctrl-1 = <0xda>;
			pinctrl-2 = <0xdb>;
			pinctrl-3 = <0xdc>;
			pinctrl-4 = <0xdd>;
			pinctrl-5 = <0xde>;
			pinctrl-6 = <0xdf>;
			mode = "hdmi";
		};

		P8_41_pinmux {
			compatible = "bone-pinmux-helper";
			status = "okay";
			pinctrl-names = "default", "gpio", "gpio_pu", "gpio_pd", "pruout", "pruin", "hdmi";
			pinctrl-0 = <0xe0>;
			pinctrl-1 = <0xe1>;
			pinctrl-2 = <0xe2>;
			pinctrl-3 = <0xe3>;
			pinctrl-4 = <0xe4>;
			pinctrl-5 = <0xe5>;
			pinctrl-6 = <0xe6>;
			mode = "hdmi";
		};

		P8_42_pinmux {
			compatible = "bone-pinmux-helper";
			status = "okay";
			pinctrl-names = "default", "gpio", "gpio_pu", "gpio_pd", "pruout", "pruin", "hdmi";
			pinctrl-0 = <0xe7>;
			pinctrl-1 = <0xe8>;
			pinctrl-2 = <0xe9>;
			pinctrl-3 = <0xea>;
			pinctrl-4 = <0xeb>;
			pinctrl-5 = <0xec>;
			pinctrl-6 = <0xed>;
			mode = "hdmi";
		};

		P8_43_pinmux {
			compatible = "bone-pinmux-helper";
			status = "okay";
			pinctrl-names = "default", "gpio", "gpio_pu", "gpio_pd", "pruout", "pruin", "pwm", "hdmi";
			pinctrl-0 = <0xee>;
			pinctrl-1 = <0xef>;
			pinctrl-2 = <0xf0>;
			pinctrl-3 = <0xf1>;
			pinctrl-4 = <0xf2>;
			pinctrl-5 = <0xf3>;
			pinctrl-6 = <0xf4>;
			pinctrl-7 = <0xf5>;
			mode = "hdmi";
		};

		P8_44_pinmux {
			compatible = "bone-pinmux-helper";
			status = "okay";
			pinctrl-names = "default", "gpio", "gpio_pu", "gpio_pd", "pruout", "pruin", "pwm", "hdmi";
			pinctrl-0 = <0xf6>;
			pinctrl-1 = <0xf7>;
			pinctrl-2 = <0xf8>;
			pinctrl-3 = <0xf9>;
			pinctrl-4 = <0xfa>;
			pinctrl-5 = <0xfb>;
			pinctrl-6 = <0xfc>;
			pinctrl-7 = <0xfd>;
			mode = "hdmi";
		};

		P8_45_pinmux {
			compatible = "bone-pinmux-helper";
			status = "okay";
			pinctrl-names = "default", "gpio", "gpio_pu", "gpio_pd", "pruout", "pruin", "pwm", "hdmi";
			pinctrl-0 = <0xfe>;
			pinctrl-1 = <0xff>;
			pinctrl-2 = <0x100>;
			pinctrl-3 = <0x101>;
			pinctrl-4 = <0x102>;
			pinctrl-5 = <0x103>;
			pinctrl-6 = <0x104>;
			pinctrl-7 = <0x105>;
			mode = "hdmi";
		};

		P8_46_pinmux {
			compatible = "bone-pinmux-helper";
			status = "okay";
			pinctrl-names = "default", "gpio", "gpio_pu", "gpio_pd", "pruout", "pruin", "pwm", "hdmi";
			pinctrl-0 = <0x106>;
			pinctrl-1 = <0x107>;
			pinctrl-2 = <0x108>;
			pinctrl-3 = <0x109>;
			pinctrl-4 = <0x10a>;
			pinctrl-5 = <0x10b>;
			pinctrl-6 = <0x10c>;
			pinctrl-7 = <0x10d>;
			mode = "hdmi";
		};

		P9_11_pinmux {
			compatible = "bone-pinmux-helper";
			status = "okay";
			pinctrl-names = "default", "gpio", "gpio_pu", "gpio_pd", "uart";
			pinctrl-0 = <0x10e>;
			pinctrl-1 = <0x10f>;
			pinctrl-2 = <0x110>;
			pinctrl-3 = <0x111>;
			pinctrl-4 = <0x112>;
		};

		P9_12_pinmux {
			compatible = "bone-pinmux-helper";
			status = "okay";
			pinctrl-names = "default", "gpio";
			pinctrl-0 = <0x113>;
			pinctrl-1 = <0x114>;
			pinctrl-2 = <0x115>;
			pinctrl-3 = <0x116>;
		};

		P9_13_pinmux {
			compatible = "bone-pinmux-helper";
			status = "okay";
			pinctrl-names = "default", "gpio", "gpio_pu", "gpio_pd", "uart";
			pinctrl-0 = <0x117>;
			pinctrl-1 = <0x118>;
			pinctrl-2 = <0x119>;
			pinctrl-3 = <0x11a>;
			pinctrl-4 = <0x11b>;
		};

		P9_14_pinmux {
			compatible = "bone-pinmux-helper";
			status = "okay";
			pinctrl-names = "default", "gpio", "gpio_pu", "gpio_pd", "pwm";
			pinctrl-0 = <0x11c>;
			pinctrl-1 = <0x11d>;
			pinctrl-2 = <0x11e>;
			pinctrl-3 = <0x11f>;
			pinctrl-4 = <0x120>;
		};

		P9_15_pinmux {
			compatible = "bone-pinmux-helper";
			status = "okay";
			pinctrl-names = "default", "gpio", "gpio_pu", "gpio_pd", "pwm";
			pinctrl-0 = <0x121>;
			pinctrl-1 = <0x122>;
			pinctrl-2 = <0x123>;
			pinctrl-3 = <0x124>;
			pinctrl-4 = <0x125>;
		};

		P9_16_pinmux {
			compatible = "bone-pinmux-helper";
			status = "okay";
			pinctrl-names = "default", "gpio", "gpio_pu", "gpio_pd", "pwm";
			pinctrl-0 = <0x126>;
			pinctrl-1 = <0x127>;
			pinctrl-2 = <0x128>;
			pinctrl-3 = <0x129>;
			pinctrl-4 = <0x12a>;
		};

		P9_17_pinmux {
			compatible = "bone-pinmux-helper";
			status = "okay";
			pinctrl-names = "default", "gpio", "gpio_pu", "gpio_pd", "spi", "i2c", "pwm";
			pinctrl-0 = <0x12b>;
			pinctrl-1 = <0x12c>;
			pinctrl-2 = <0x12d>;
			pinctrl-3 = <0x12e>;
			pinctrl-4 = <0x12f>;
			pinctrl-5 = <0x130>;
			pinctrl-6 = <0x131>;
		};

		P9_18_pinmux {
			compatible = "bone-pinmux-helper";
			status = "okay";
			pinctrl-names = "default", "gpio", "gpio_pu", "gpio_pd", "spi", "i2c", "pwm";
			pinctrl-0 = <0x132>;
			pinctrl-1 = <0x133>;
			pinctrl-2 = <0x134>;
			pinctrl-3 = <0x135>;
			pinctrl-4 = <0x136>;
			pinctrl-5 = <0x137>;
			pinctrl-6 = <0x138>;
		};

		P9_21_pinmux {
			compatible = "bone-pinmux-helper";
			status = "okay";
			pinctrl-names = "default", "gpio", "gpio_pu", "gpio_pd", "spi", "uart", "i2c", "pwm";
			pinctrl-0 = <0x139>;
			pinctrl-1 = <0x13a>;
			pinctrl-2 = <0x13b>;
			pinctrl-3 = <0x13c>;
			pinctrl-4 = <0x13d>;
			pinctrl-5 = <0x13e>;
			pinctrl-6 = <0x13f>;
			pinctrl-7 = <0x140>;
			mode = "uart";
		};

		P9_22_pinmux {
			compatible = "bone-pinmux-helper";
			status = "okay";
			pinctrl-names = "default", "gpio", "gpio_pu", "gpio_pd", "spi", "uart", "i2c", "pwm";
			pinctrl-0 = <0x141>;
			pinctrl-1 = <0x142>;
			pinctrl-2 = <0x143>;
			pinctrl-3 = <0x144>;
			pinctrl-4 = <0x145>;
			pinctrl-5 = <0x146>;
			pinctrl-6 = <0x147>;
			pinctrl-7 = <0x148>;
			mode = "uart";
		};

		P9_23_pinmux {
			compatible = "bone-pinmux-helper";
			status = "okay";
			pinctrl-names = "default", "gpio", "gpio_pu", "gpio_pd", "pwm";
			pinctrl-0 = <0x149>;
			pinctrl-1 = <0x14a>;
			pinctrl-2 = <0x14b>;
			pinctrl-3 = <0x14c>;
			pinctrl-4 = <0x14d>;
		};

		P9_24_pinmux {
			compatible = "bone-pinmux-helper";
			status = "okay";
			pinctrl-names = "default", "gpio", "gpio_pu", "gpio_pd", "uart", "can", "i2c", "pruin";
			pinctrl-0 = <0x14e>;
			pinctrl-1 = <0x14f>;
			pinctrl-2 = <0x150>;
			pinctrl-3 = <0x151>;
			pinctrl-4 = <0x152>;
			pinctrl-5 = <0x153>;
			pinctrl-6 = <0x154>;
			pinctrl-7 = <0x155>;
		};

		P9_25_pinmux {
			compatible = "bone-pinmux-helper";
			status = "okay";
			pinctrl-names = "default", "gpio", "gpio_pu", "gpio_pd", "qep", "pruout", "pruin", "audio";
			pinctrl-0 = <0x156>;
			pinctrl-1 = <0x157>;
			pinctrl-2 = <0x158>;
			pinctrl-3 = <0x159>;
			pinctrl-4 = <0x15a>;
			pinctrl-5 = <0x15b>;
			pinctrl-6 = <0x15c>;
			pinctrl-7 = <0x15d>;
			mode = "audio";
		};

		P9_26_pinmux {
			compatible = "bone-pinmux-helper";
			status = "okay";
			pinctrl-names = "default", "gpio", "gpio_pu", "gpio_pd", "uart", "can", "i2c", "pruin";
			pinctrl-0 = <0x15e>;
			pinctrl-1 = <0x15f>;
			pinctrl-2 = <0x160>;
			pinctrl-3 = <0x161>;
			pinctrl-4 = <0x162>;
			pinctrl-5 = <0x163>;
			pinctrl-6 = <0x164>;
			pinctrl-7 = <0x165>;
		};

		P9_27_pinmux {
			compatible = "bone-pinmux-helper";
			status = "okay";
			pinctrl-names = "default", "gpio", "gpio_pu", "gpio_pd", "qep", "pruout", "pruin";
			pinctrl-0 = <0x166>;
			pinctrl-1 = <0x167>;
			pinctrl-2 = <0x168>;
			pinctrl-3 = <0x169>;
			pinctrl-4 = <0x16a>;
			pinctrl-5 = <0x16b>;
			pinctrl-6 = <0x16c>;
		};

		P9_28_pinmux {
			compatible = "bone-pinmux-helper";
			status = "okay";
			pinctrl-names = "default", "gpio", "gpio_pu", "gpio_pd", "pwm", "spi", "pwm2", "pruout", "pruin", "audio";
			pinctrl-0 = <0x16d>;
			pinctrl-1 = <0x16e>;
			pinctrl-2 = <0x16f>;
			pinctrl-3 = <0x170>;
			pinctrl-4 = <0x171>;
			pinctrl-5 = <0x172>;
			pinctrl-6 = <0x173>;
			pinctrl-7 = <0x174>;
			pinctrl-8 = <0x175>;
			pinctrl-9 = <0x176>;
			mode = "audio";
		};

		P9_29_pinmux {
			compatible = "bone-pinmux-helper";
			status = "okay";
			pinctrl-names = "default", "gpio", "gpio_pu", "gpio_pd", "pwm", "spi", "pruout", "pruin", "audio";
			pinctrl-0 = <0x177>;
			pinctrl-1 = <0x178>;
			pinctrl-2 = <0x179>;
			pinctrl-3 = <0x17a>;
			pinctrl-4 = <0x17b>;
			pinctrl-5 = <0x17c>;
			pinctrl-6 = <0x17d>;
			pinctrl-7 = <0x17e>;
			pinctrl-8 = <0x17f>;
			mode = "audio";
		};

		P9_30_pinmux {
			compatible = "bone-pinmux-helper";
			status = "okay";
			pinctrl-names = "default", "gpio", "gpio_pu", "gpio_pd", "pwm", "spi", "pruout", "pruin";
			pinctrl-0 = <0x180>;
			pinctrl-1 = <0x181>;
			pinctrl-2 = <0x182>;
			pinctrl-3 = <0x183>;
			pinctrl-4 = <0x184>;
			pinctrl-5 = <0x185>;
			pinctrl-6 = <0x186>;
			pinctrl-7 = <0x187>;
		};

		P9_31_pinmux {
			compatible = "bone-pinmux-helper";
			status = "okay";
			pinctrl-names = "default", "gpio", "gpio_pu", "gpio_pd", "pwm", "spi", "pruout", "pruin", "audio";
			pinctrl-0 = <0x188>;
			pinctrl-1 = <0x189>;
			pinctrl-2 = <0x18a>;
			pinctrl-3 = <0x18b>;
			pinctrl-4 = <0x18c>;
			pinctrl-5 = <0x18d>;
			pinctrl-6 = <0x18e>;
			pinctrl-7 = <0x18f>;
			pinctrl-8 = <0x190>;
			mode = "audio";
		};

		P9_41_pinmux {
			compatible = "bone-pinmux-helper";
			status = "disabled";
			pinctrl-names = "default", "gpio", "gpio_pu", "gpio_pd", "timer", "pruin";
			pinctrl-0 = <0x191>;
			pinctrl-1 = <0x192>;
			pinctrl-2 = <0x193>;
			pinctrl-3 = <0x194>;
			pinctrl-4 = <0x195>;
			pinctrl-5 = <0x196>;
			mode = "audio";
		};

		P9_91_pinmux {
			compatible = "bone-pinmux-helper";
			status = "okay";
			pinctrl-names = "default", "gpio", "gpio_pu", "gpio_pd", "qep", "pruout", "pruin";
			pinctrl-0 = <0x197>;
			pinctrl-1 = <0x198>;
			pinctrl-2 = <0x199>;
			pinctrl-3 = <0x19a>;
			pinctrl-4 = <0x19b>;
			pinctrl-5 = <0x19c>;
			pinctrl-6 = <0x19d>;
		};

		P9_42_pinmux {
			compatible = "bone-pinmux-helper";
			status = "okay";
			pinctrl-names = "default", "gpio", "gpio_pu", "gpio_pd", "pwm", "uart", "spics", "spiclk";
			pinctrl-0 = <0x19e>;
			pinctrl-1 = <0x19f>;
			pinctrl-2 = <0x1a0>;
			pinctrl-3 = <0x1a1>;
			pinctrl-4 = <0x1a2>;
			pinctrl-5 = <0x1a3>;
			pinctrl-6 = <0x1a4>;
			pinctrl-7 = <0x1a5>;
		};

		P9_92_pinmux {
			compatible = "bone-pinmux-helper";
			status = "disabled";
			pinctrl-names = "default", "gpio", "gpio_pu", "gpio_pd", "qep", "pruout", "pruin";
			pinctrl-0 = <0x1a6>;
			pinctrl-1 = <0x1a7>;
			pinctrl-2 = <0x1a8>;
			pinctrl-3 = <0x1a9>;
			pinctrl-4 = <0x1aa>;
			pinctrl-5 = <0x1ab>;
			pinctrl-6 = <0x1ac>;
		};

		cape-universal {
			compatible = "gpio-of-helper";
			status = "okay";
			pinctrl-names = "default";
			pinctrl-0;

			P8_07 {
				gpio-name = "P8_07";
				gpio = <0x1ad 0x2 0x0>;
				input;
				dir-changeable;
			};

			P8_08 {
				gpio-name = "P8_08";
				gpio = <0x1ad 0x3 0x0>;
				input;
				dir-changeable;
			};

			P8_09 {
				gpio-name = "P8_09";
				gpio = <0x1ad 0x5 0x0>;
				input;
				dir-changeable;
			};

			P8_10 {
				gpio-name = "P8_10";
				gpio = <0x1ad 0x4 0x0>;
				input;
				dir-changeable;
			};

			P8_11 {
				gpio-name = "P8_11";
				gpio = <0x1ae 0xd 0x0>;
				input;
				dir-changeable;
			};

			P8_12 {
				gpio-name = "P8_12";
				gpio = <0x1ae 0xc 0x0>;
				input;
				dir-changeable;
			};

			P8_13 {
				gpio-name = "P8_13";
				gpio = <0x2b 0x17 0x0>;
				input;
				dir-changeable;
			};

			P8_14 {
				gpio-name = "P8_14";
				gpio = <0x2b 0x1a 0x0>;
				input;
				dir-changeable;
			};

			P8_15 {
				gpio-name = "P8_15";
				gpio = <0x1ae 0xf 0x0>;
				input;
				dir-changeable;
			};

			P8_16 {
				gpio-name = "P8_16";
				gpio = <0x1ae 0xe 0x0>;
				input;
				dir-changeable;
			};

			P8_17 {
				gpio-name = "P8_17";
				gpio = <0x2b 0x1b 0x0>;
				input;
				dir-changeable;
			};

			P8_18 {
				gpio-name = "P8_18";
				gpio = <0x1ad 0x1 0x0>;
				input;
				dir-changeable;
			};

			P8_19 {
				gpio-name = "P8_19";
				gpio = <0x2b 0x16 0x0>;
				input;
				dir-changeable;
			};

			P8_26 {
				gpio-name = "P8_26";
				gpio = <0x1ae 0x1d 0x0>;
				input;
				dir-changeable;
			};

			P8_27 {
				gpio-name = "P8_27";
				gpio = <0x1ad 0x16 0x0>;
				input;
				dir-changeable;
			};

			P8_28 {
				gpio-name = "P8_28";
				gpio = <0x1ad 0x18 0x0>;
				input;
				dir-changeable;
			};

			P8_29 {
				gpio-name = "P8_29";
				gpio = <0x1ad 0x17 0x0>;
				input;
				dir-changeable;
			};

			P8_30 {
				gpio-name = "P8_30";
				gpio = <0x1ad 0x19 0x0>;
				input;
				dir-changeable;
			};

			P8_31 {
				gpio-name = "P8_31";
				gpio = <0x2b 0xa 0x0>;
				input;
				dir-changeable;
			};

			P8_32 {
				gpio-name = "P8_32";
				gpio = <0x2b 0xb 0x0>;
				input;
				dir-changeable;
			};

			P8_33 {
				gpio-name = "P8_33";
				gpio = <0x2b 0x9 0x0>;
				input;
				dir-changeable;
			};

			P8_34 {
				gpio-name = "P8_34";
				gpio = <0x1ad 0x11 0x0>;
				input;
				dir-changeable;
			};

			P8_35 {
				gpio-name = "P8_35";
				gpio = <0x2b 0x8 0x0>;
				input;
				dir-changeable;
			};

			P8_36 {
				gpio-name = "P8_36";
				gpio = <0x1ad 0x10 0x0>;
				input;
				dir-changeable;
			};

			P8_37 {
				gpio-name = "P8_37";
				gpio = <0x1ad 0xe 0x0>;
				input;
				dir-changeable;
			};

			P8_38 {
				gpio-name = "P8_38";
				gpio = <0x1ad 0xf 0x0>;
				input;
				dir-changeable;
			};

			P8_39 {
				gpio-name = "P8_39";
				gpio = <0x1ad 0xc 0x0>;
				input;
				dir-changeable;
			};

			P8_40 {
				gpio-name = "P8_40";
				gpio = <0x1ad 0xd 0x0>;
				input;
				dir-changeable;
			};

			P8_41 {
				gpio-name = "P8_41";
				gpio = <0x1ad 0xa 0x0>;
				input;
				dir-changeable;
			};

			P8_42 {
				gpio-name = "P8_42";
				gpio = <0x1ad 0xb 0x0>;
				input;
				dir-changeable;
			};

			P8_43 {
				gpio-name = "P8_43";
				gpio = <0x1ad 0x8 0x0>;
				input;
				dir-changeable;
			};

			P8_44 {
				gpio-name = "P8_44";
				gpio = <0x1ad 0x9 0x0>;
				input;
				dir-changeable;
			};

			P8_45 {
				gpio-name = "P8_45";
				gpio = <0x1ad 0x6 0x0>;
				input;
				dir-changeable;
			};

			P8_46 {
				gpio-name = "P8_46";
				gpio = <0x1ad 0x7 0x0>;
				input;
				dir-changeable;
			};

			P9_11 {
				gpio-name = "P9_11";
				gpio = <0x2b 0x1e 0x0>;
				input;
				dir-changeable;
			};

			P9_12 {
				gpio-name = "P9_12";
				gpio = <0x1ae 0x1c 0x0>;
				input;
				dir-changeable;
			};

			P9_13 {
				gpio-name = "P9_13";
				gpio = <0x2b 0x1f 0x0>;
				input;
				dir-changeable;
			};

			P9_14 {
				gpio-name = "P9_14";
				gpio = <0x1ae 0x12 0x0>;
				input;
				dir-changeable;
			};

			P9_15 {
				gpio-name = "P9_15";
				gpio = <0x1ae 0x10 0x0>;
				input;
				dir-changeable;
			};

			P9_16 {
				gpio-name = "P9_16";
				gpio = <0x1ae 0x13 0x0>;
				input;
				dir-changeable;
			};

			P9_17 {
				gpio-name = "P9_17";
				gpio = <0x2b 0x5 0x0>;
				input;
				dir-changeable;
			};

			P9_18 {
				gpio-name = "P9_18";
				gpio = <0x2b 0x4 0x0>;
				input;
				dir-changeable;
			};

			P9_21 {
				gpio-name = "P9_21";
				gpio = <0x2b 0x3 0x0>;
				input;
				dir-changeable;
			};

			P9_22 {
				gpio-name = "P9_22";
				gpio = <0x2b 0x2 0x0>;
				input;
				dir-changeable;
			};

			P9_23 {
				gpio-name = "P9_23";
				gpio = <0x1ae 0x11 0x0>;
				input;
				dir-changeable;
			};

			P9_24 {
				gpio-name = "P9_24";
				gpio = <0x2b 0xf 0x0>;
				input;
				dir-changeable;
			};

			P9_25 {
				gpio-name = "P9_25";
				gpio = <0x1af 0x15 0x0>;
				input;
				dir-changeable;
			};

			P9_26 {
				gpio-name = "P9_26";
				gpio = <0x2b 0xe 0x0>;
				input;
				dir-changeable;
			};

			P9_27 {
				gpio-name = "P9_27";
				gpio = <0x1af 0x13 0x0>;
				input;
				dir-changeable;
			};

			P9_28 {
				gpio-name = "P9_28";
				gpio = <0x1af 0x11 0x0>;
				input;
				dir-changeable;
			};

			P9_29 {
				gpio-name = "P9_29";
				gpio = <0x1af 0xf 0x0>;
				input;
				dir-changeable;
			};

			P9_30 {
				gpio-name = "P9_30";
				gpio = <0x1af 0x10 0x0>;
				input;
				dir-changeable;
			};

			P9_31 {
				gpio-name = "P9_31";
				gpio = <0x1af 0xe 0x0>;
				input;
				dir-changeable;
			};

			P9_41 {
				gpio-name = "P9_41";
				gpio = <0x2b 0x14 0x0>;
				input;
				dir-changeable;
			};

			P9_91 {
				gpio-name = "P9_91";
				gpio = <0x1af 0x14 0x0>;
				input;
				dir-changeable;
			};

			P9_42 {
				gpio-name = "P9_42";
				gpio = <0x2b 0x7 0x0>;
				input;
				dir-changeable;
			};

			P9_92 {
				gpio-name = "P9_92";
				gpio = <0x1af 0x12 0x0>;
				input;
				dir-changeable;
			};
		};
	};

	leds {
		pinctrl-names = "default", "sleep";
		pinctrl-0 = <0x1b0>;
		pinctrl-1 = <0x1b1>;
		compatible = "gpio-leds";

		led@2 {
			label = "beaglebone:green:usr0";
			gpios = <0x1ae 0x15 0x0>;
			linux,default-trigger = "heartbeat";
			default-state = "off";
		};

		led@3 {
			label = "beaglebone:green:usr1";
			gpios = <0x1ae 0x16 0x0>;
			linux,default-trigger = "mmc0";
			default-state = "off";
		};

		led@4 {
			label = "beaglebone:green:usr2";
			gpios = <0x1ae 0x17 0x0>;
			linux,default-trigger = "cpu0";
			default-state = "off";
		};

		led@5 {
			label = "beaglebone:green:usr3";
			gpios = <0x1ae 0x18 0x0>;
			linux,default-trigger = "mmc1";
			default-state = "off";
		};
	};

	fixedregulator@0 {
		compatible = "regulator-fixed";
		regulator-name = "vbat";
		regulator-min-microvolt = <0x4c4b40>;
		regulator-max-microvolt = <0x4c4b40>;
		regulator-boot-on;
	};

	fixedregulator@1 {
		compatible = "regulator-fixed";
		regulator-name = "vmmcsd_fixed";
		regulator-min-microvolt = <0x325aa0>;
		regulator-max-microvolt = <0x325aa0>;
		linux,phandle = <0x2c>;
		phandle = <0x2c>;
	};

	hdmi {
		compatible = "ti,tilcdc,slave";
		i2c = <0x1b2>;
		pinctrl-names = "default", "off";
		pinctrl-0 = <0x1b3>;
		pinctrl-1 = <0x1b3>;
		status = "okay";
	};

	clk_mcasp0_fixed {
		#clock-cells = <0x0>;
		compatible = "fixed-clock";
		clock-frequency = <0x1770000>;
		linux,phandle = <0x1b4>;
		phandle = <0x1b4>;
	};

	clk_mcasp0 {
		#clock-cells = <0x0>;
		compatible = "ti,gpio-gate-clock";
		clocks = <0x1b4>;
		enable-gpios = <0x1ae 0x1b 0x0>;
		linux,phandle = <0x1b7>;
		phandle = <0x1b7>;
	};

	hdmi_audio@0 {
		compatible = "linux,hdmi-audio";
		status = "okay";
		linux,phandle = <0x1b5>;
		phandle = <0x1b5>;
	};

	sound {
		compatible = "ti,beaglebone-black-audio";
		ti,model = "TI BeagleBone Black";
		ti,audio-codec = <0x1b5>;
		ti,mcasp-controller = <0x1b6>;
		ti,audio-routing = "HDMI Out", "TX";
		clocks = <0x1b7>;
		clock-names = "mclk";
	};
};
